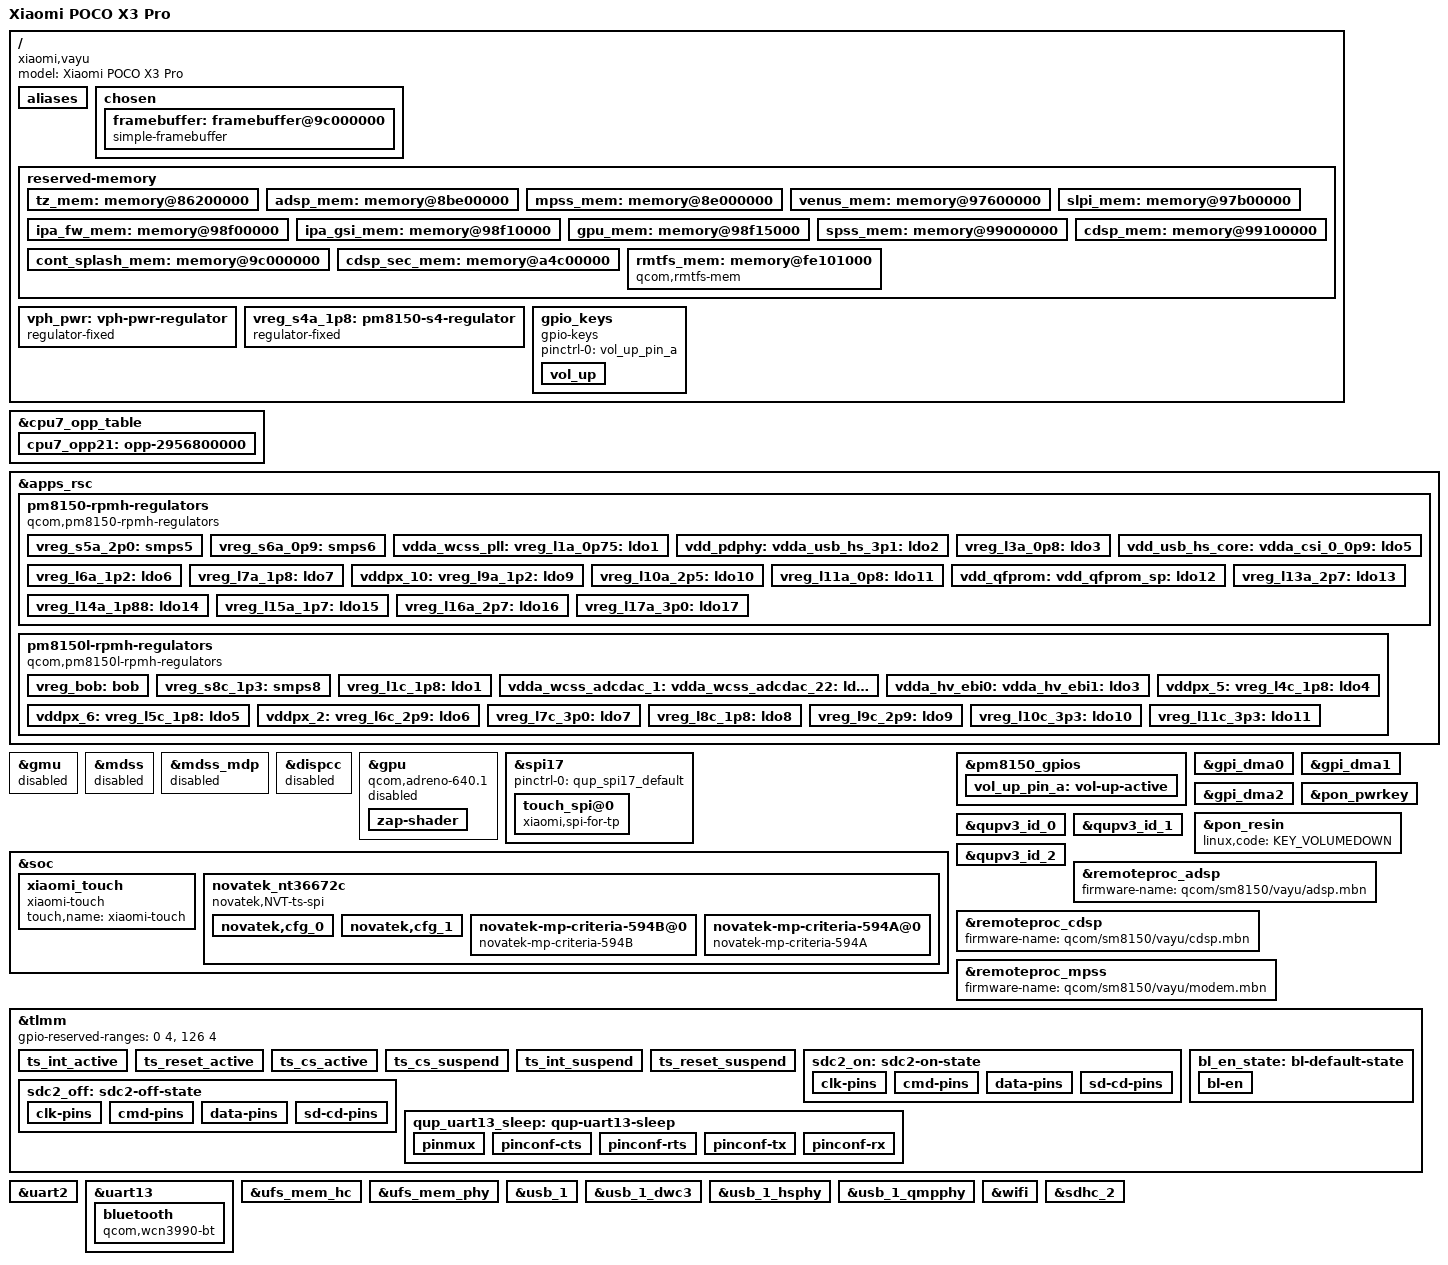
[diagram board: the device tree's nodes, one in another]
// SPDX-License-Identifier: GPL-2.0
/*
 * Device Tree Source for Xiaomi POCO X3 Pro (vayu)
 *
 * Copyright (c) 2023, Arseniy Velikanov <adomerlee@gmail.com>
 */

/dts-v1/;

#include <dt-bindings/gpio/gpio.h>
#include <dt-bindings/input/input.h>
#include <dt-bindings/input/gpio-keys.h>
#include <dt-bindings/pinctrl/qcom,pmic-gpio.h>
#include <dt-bindings/regulator/qcom,rpmh-regulator.h>
#include "sm8150.dtsi"
#include "pm8150.dtsi"
#include "pm8150b.dtsi"
#include "pm8150l.dtsi"

/* 
 * Rewrite reserved memory maps inherited from sm8150.dtsi to match the ones
 * used on xiaomi-vayu.
 * Note: this list is ordered by its memory address in sm8150.dtsi.
 */
/delete-node/ &tz_mem;      /* same address but larger, no place for rmtfs_mem! */
/delete-node/ &rmtfs_mem;   /* moved to completely different address */
/delete-node/ &adsp_mem;    /* same start address, but larger size */
/delete-node/ &mpss_mem;    /* same size, shifted higher, due to larger adsp_mem */
/delete-node/ &venus_mem;   /* same size, shifted higher */
/delete-node/ &slpi_mem;    /* same size, shifted higher */
/delete-node/ &ipa_fw_mem;  /* same size, shifted higher */
/delete-node/ &ipa_gsi_mem; /* same size, shifted higher */
/delete-node/ &gpu_mem;     /* same size, shifted higher */
/delete-node/ &spss_mem;    /* same size, shifted higher */
/delete-node/ &cdsp_mem;    /* same size, shifted higher */

/ {
	model = "Xiaomi POCO X3 Pro";
	compatible = "xiaomi,vayu", "qcom,sm8150";

	aliases {
		serial0 = &uart2;
		display0 = &framebuffer;
	};

	chosen {
		#address-cells = <2>;
		#size-cells = <2>;
		ranges;
	
		framebuffer: framebuffer@9c000000 {
			compatible = "simple-framebuffer";
			reg = <0 0x9c000000 0 (1080 * 2400 * 4)>;
			width = <1080>;
			height = <2400>;
			stride = <(1080 * 4)>;
			format = "a8r8g8b8";
			/*
			 * That's (going to be) a lot of clocks, but it's necessary due
			 * to unused clk cleanup & no panel driver yet (& no dispcc either)..
			 */
			clocks = <&gcc GCC_DISP_HF_AXI_CLK>,
			    	 <&gcc GCC_DISP_SF_AXI_CLK>;
		};
	};
	

	reserved-memory {
		tz_mem: memory@86200000 {
			reg = <0x0 0x86200000 0x0 0x5500000>;
			no-map;
		};

		adsp_mem: memory@8be00000 {
			no-map;
			reg = <0x0 0x8be00000 0x0 0x2200000>;
		};

		mpss_mem: memory@8e000000 {
			no-map;
			reg = <0x0 0x8e000000 0x0 0x9600000>;
		};

		venus_mem: memory@97600000 {
			no-map;
			reg = <0x0 0x97600000 0x0 0x500000>;
		};

		slpi_mem: memory@97b00000 {
			no-map;
			reg = <0x0 0x97b00000 0x0 0x1400000>;
		};

		ipa_fw_mem: memory@98f00000 {
			no-map;
			reg = <0x0 0x98f00000 0x0 0x10000>;
		};

		ipa_gsi_mem: memory@98f10000 {
			no-map;
			reg = <0x0 0x98f10000 0x0 0x5000>;
		};

		gpu_mem: memory@98f15000 {
			no-map;
			reg = <0x0 0x98f15000 0x0 0x2000>;
		};

		spss_mem: memory@99000000 {
			no-map;
			reg = <0x0 0x99000000 0x0 0x100000>;
		};

		cdsp_mem: memory@99100000 {
			no-map;
			reg = <0x0 0x99100000 0x0 0x1400000>;
		};

		cont_splash_mem: memory@9c000000 {
			reg = <0x0 0x9c000000 0x0 0x2400000>;
			no-map;
		};

		cdsp_sec_mem: memory@a4c00000 {
			reg = <0x0 0xa4c00000 0x0 0x3c00000>;
			no-map;
		};
		
		rmtfs_mem: memory@fe101000 {
			compatible = "qcom,rmtfs-mem";
			reg = <0 0xfe101000 0 0x300000>;
			no-map;

			qcom,client-id = <1>;
			qcom,vmid = <15>;
		};
	};

	vph_pwr: vph-pwr-regulator {
		compatible = "regulator-fixed";
		regulator-name = "vph_pwr";
		regulator-min-microvolt = <3700000>;
		regulator-max-microvolt = <3700000>;
	};

	/* S4 is modeled as a fixed regulator in vendor sources */
	vreg_s4a_1p8: pm8150-s4-regulator {
		compatible = "regulator-fixed";
		regulator-name = "vreg_s4a_1p8";

		regulator-min-microvolt = <1800000>;
		regulator-max-microvolt = <1800000>;

		regulator-always-on;
		regulator-boot-on;

		vin-supply = <&vph_pwr>;
	};
	
	gpio_keys {
		compatible = "gpio-keys";
		pinctrl-names = "default";
		pinctrl-0 = <&vol_up_pin_a>;
		
		vol_up {
			label = "volume_up";
			gpios = <&pm8150_gpios 6 GPIO_ACTIVE_LOW>;
			linux,input-type = <EV_KEY>;
			linux,code = <KEY_VOLUMEUP>;
			wakeup-source;
			debounce-interval = <15>;
		};
	};
};

//SD860 additional cpu frequency
&cpu7_opp_table {
	cpu7_opp21: opp-2956800000 {
		opp-hz = /bits/ 64 <2956800000>;
		opp-peak-kBps = <8368000 51609600>;
	};
};

&apps_rsc {
	pm8150-rpmh-regulators {
		compatible = "qcom,pm8150-rpmh-regulators";
		qcom,pmic-id = "a";

		vdd-s1-supply = <&vph_pwr>;
		vdd-s2-supply = <&vph_pwr>;
		vdd-s3-supply = <&vph_pwr>;
		vdd-s4-supply = <&vph_pwr>;
		vdd-s5-supply = <&vph_pwr>;
		vdd-s6-supply = <&vph_pwr>;
		vdd-s7-supply = <&vph_pwr>;
		vdd-s8-supply = <&vph_pwr>;
		vdd-s9-supply = <&vph_pwr>;
		vdd-s10-supply = <&vph_pwr>;

		vdd-l1-l8-l11-supply = <&vreg_s6a_0p9>;
		vdd-l2-l10-supply = <&vreg_bob>;
		vdd-l3-l4-l5-l18-supply = <&vreg_s6a_0p9>;
		vdd-l6-l9-supply = <&vreg_s8c_1p3>;
		vdd-l7-l12-l14-l15-supply = <&vreg_s5a_2p0>;
		vdd-l13-l16-l17-supply = <&vreg_bob>;

		vreg_s5a_2p0: smps5 {
			regulator-min-microvolt = <1904000>;
			regulator-max-microvolt = <2000000>;
		};

		vreg_s6a_0p9: smps6 {
			regulator-min-microvolt = <920000>;
			regulator-max-microvolt = <1128000>;
		};

		vdda_wcss_pll:
		vreg_l1a_0p75: ldo1 {
			regulator-min-microvolt = <752000>;
			regulator-max-microvolt = <752000>;
			regulator-initial-mode = <RPMH_REGULATOR_MODE_HPM>;
		};

		vdd_pdphy:
		vdda_usb_hs_3p1:
		vreg_l2a_3p1: ldo2 {
			regulator-min-microvolt = <3072000>;
			regulator-max-microvolt = <3072000>;
			regulator-initial-mode = <RPMH_REGULATOR_MODE_HPM>;
		};

		vreg_l3a_0p8: ldo3 {
			regulator-min-microvolt = <480000>;
			regulator-max-microvolt = <932000>;
			regulator-initial-mode = <RPMH_REGULATOR_MODE_HPM>;
		};

		vdd_usb_hs_core:
		vdda_csi_0_0p9:
		vdda_csi_1_0p9:
		vdda_csi_2_0p9:
		vdda_csi_3_0p9:
		vdda_dsi_0_0p9:
		vdda_dsi_1_0p9:
		vdda_dsi_0_pll_0p9:
		vdda_dsi_1_pll_0p9:
		vdda_pcie_1ln_core:
		vdda_pcie_2ln_core:
		vdda_pll_hv_cc_ebi01:
		vdda_pll_hv_cc_ebi23:
		vdda_qrefs_0p875_5:
		vdda_sp_sensor:
		vdda_ufs_2ln_core_1:
		vdda_ufs_2ln_core_2:
		vdda_usb_ss_dp_core_1:
		vdda_usb_ss_dp_core_2:
		vdda_qlink_lv:
		vdda_qlink_lv_ck:
		vreg_l5a_0p875: ldo5 {
			regulator-min-microvolt = <880000>;
			regulator-max-microvolt = <880000>;
			regulator-initial-mode = <RPMH_REGULATOR_MODE_HPM>;
		};

		vreg_l6a_1p2: ldo6 {
			regulator-min-microvolt = <1200000>;
			regulator-max-microvolt = <1200000>;
			regulator-initial-mode = <RPMH_REGULATOR_MODE_HPM>;
		};

		vreg_l7a_1p8: ldo7 {
			regulator-min-microvolt = <1800000>;
			regulator-max-microvolt = <1800000>;
			regulator-initial-mode = <RPMH_REGULATOR_MODE_HPM>;
		};

		vddpx_10:
		vreg_l9a_1p2: ldo9 {
			regulator-min-microvolt = <1200000>;
			regulator-max-microvolt = <1200000>;
			regulator-initial-mode = <RPMH_REGULATOR_MODE_HPM>;
		};

		vreg_l10a_2p5: ldo10 {
			regulator-min-microvolt = <2504000>;
			regulator-max-microvolt = <2960000>;
			regulator-initial-mode = <RPMH_REGULATOR_MODE_HPM>;
		};

		vreg_l11a_0p8: ldo11 {
			regulator-min-microvolt = <800000>;
			regulator-max-microvolt = <800000>;
			regulator-initial-mode = <RPMH_REGULATOR_MODE_HPM>;
		};

		vdd_qfprom:
		vdd_qfprom_sp:
		vdda_apc_cs_1p8:
		vdda_gfx_cs_1p8:
		vdda_usb_hs_1p8:
		vdda_qrefs_vref_1p8:
		vddpx_10_a:
		vreg_l12a_1p8: ldo12 {
			regulator-min-microvolt = <1800000>;
			regulator-max-microvolt = <1800000>;
			regulator-initial-mode = <RPMH_REGULATOR_MODE_HPM>;
		};

		vreg_l13a_2p7: ldo13 {
			regulator-min-microvolt = <2704000>;
			regulator-max-microvolt = <2704000>;
			regulator-initial-mode = <RPMH_REGULATOR_MODE_HPM>;
		};

		vreg_l14a_1p88: ldo14 {
			regulator-min-microvolt = <1800000>;
			regulator-max-microvolt = <1880000>;
			regulator-initial-mode = <RPMH_REGULATOR_MODE_HPM>;
		};

		vreg_l15a_1p7: ldo15 {
			regulator-min-microvolt = <1704000>;
			regulator-max-microvolt = <1704000>;
			regulator-initial-mode = <RPMH_REGULATOR_MODE_HPM>;
		};

		vreg_l16a_2p7: ldo16 {
			regulator-min-microvolt = <2704000>;
			regulator-max-microvolt = <2960000>;
			regulator-initial-mode = <RPMH_REGULATOR_MODE_HPM>;
		};

		vreg_l17a_3p0: ldo17 {
			regulator-min-microvolt = <2856000>;
			regulator-max-microvolt = <3008000>;
			regulator-initial-mode = <RPMH_REGULATOR_MODE_HPM>;
		};
	};

	pm8150l-rpmh-regulators {
		compatible = "qcom,pm8150l-rpmh-regulators";
		qcom,pmic-id = "c";

		vdd-s1-supply = <&vph_pwr>;
		vdd-s2-supply = <&vph_pwr>;
		vdd-s3-supply = <&vph_pwr>;
		vdd-s4-supply = <&vph_pwr>;
		vdd-s5-supply = <&vph_pwr>;
		vdd-s6-supply = <&vph_pwr>;
		vdd-s7-supply = <&vph_pwr>;
		vdd-s8-supply = <&vph_pwr>;

		vdd-l1-l8-supply = <&vreg_s4a_1p8>;
		vdd-l2-l3-supply = <&vreg_s8c_1p3>;
		vdd-l4-l5-l6-supply = <&vreg_bob>;
		vdd-l7-l11-supply = <&vreg_bob>;
		vdd-l9-l10-supply = <&vreg_bob>;

		vdd-bob-supply = <&vph_pwr>;
		vdd-flash-supply = <&vreg_bob>;
		vdd-rgb-supply = <&vreg_bob>;

		vreg_bob: bob {
			regulator-min-microvolt = <3008000>;
			regulator-max-microvolt = <4000000>;
			regulator-initial-mode = <RPMH_REGULATOR_MODE_AUTO>;
			regulator-allow-bypass;
		};

		vreg_s8c_1p3: smps8 {
			regulator-min-microvolt = <1352000>;
			regulator-max-microvolt = <1352000>;
		};

		vreg_l1c_1p8: ldo1 {
			regulator-min-microvolt = <1800000>;
			regulator-max-microvolt = <1800000>;
			regulator-initial-mode = <RPMH_REGULATOR_MODE_HPM>;
		};

		vdda_wcss_adcdac_1:
		vdda_wcss_adcdac_22:
		vreg_l2c_1p3: ldo2 {
			regulator-min-microvolt = <1304000>;
			regulator-max-microvolt = <1304000>;
			regulator-initial-mode = <RPMH_REGULATOR_MODE_HPM>;
		};

		vdda_hv_ebi0:
		vdda_hv_ebi1:
		vdda_hv_ebi2:
		vdda_hv_ebi3:
		vdda_hv_refgen0:
		vdda_mipi_dsi0_1p2:
		vdda_mipi_dsi1_1p2:
		vdda_qlink_hv_ck:
		vreg_l3c_1p2: ldo3 {
			regulator-min-microvolt = <1200000>;
			regulator-max-microvolt = <1200000>;
			regulator-initial-mode = <RPMH_REGULATOR_MODE_HPM>;
		};

		vddpx_5:
		vreg_l4c_1p8: ldo4 {
			regulator-min-microvolt = <1704000>;
			regulator-max-microvolt = <2928000>;
			regulator-initial-mode = <RPMH_REGULATOR_MODE_HPM>;
		};

		vddpx_6:
		vreg_l5c_1p8: ldo5 {
			regulator-min-microvolt = <1704000>;
			regulator-max-microvolt = <2928000>;
			regulator-initial-mode = <RPMH_REGULATOR_MODE_HPM>;
		};

		vddpx_2:
		vreg_l6c_2p9: ldo6 {
			regulator-min-microvolt = <1800000>;
			regulator-max-microvolt = <2960000>;
			regulator-initial-mode = <RPMH_REGULATOR_MODE_HPM>;
		};

		vreg_l7c_3p0: ldo7 {
			regulator-min-microvolt = <2856000>;
			regulator-max-microvolt = <3104000>;
			regulator-initial-mode = <RPMH_REGULATOR_MODE_HPM>;
		};

		vreg_l8c_1p8: ldo8 {
			regulator-min-microvolt = <1800000>;
			regulator-max-microvolt = <1800000>;
			regulator-initial-mode = <RPMH_REGULATOR_MODE_HPM>;
		};

		vreg_l9c_2p9: ldo9 {
			regulator-min-microvolt = <2704000>;
			regulator-max-microvolt = <2960000>;
			regulator-initial-mode = <RPMH_REGULATOR_MODE_HPM>;
		};

		vreg_l10c_3p3: ldo10 {
			regulator-min-microvolt = <3000000>;
			regulator-max-microvolt = <3312000>;
			regulator-initial-mode = <RPMH_REGULATOR_MODE_HPM>;
		};

		vreg_l11c_3p3: ldo11 {
			regulator-min-microvolt = <3000000>;
			regulator-max-microvolt = <3312000>;
			regulator-initial-mode = <RPMH_REGULATOR_MODE_HPM>;
		};
	};
};

&gmu {
	status = "disabled";
};

&mdss {
	status = "disabled";
};

&mdss_mdp {
	status = "disabled";
};

&dispcc {
	status = "disabled";
};

&gpu {
	/*
	 * NOTE: "amd,imageon" makes Adreno start in headless mode, remove it
	 * after display support is added on this board.
	 */
	compatible = "qcom,adreno-640.1", "qcom,adreno", "amd,imageon";

	status = "disabled";
	
	zap-shader {
		memory-region = <&gpu_mem>;
		firmware-name = "qcom/a640_zap.mbn";
	};
};

&spi17 {
	status = "okay";
	pinctrl-0 = <&qup_spi17_default>;
	
	touch_spi@0 {
		compatible = "xiaomi,spi-for-tp";
		reg = <0>;
		status = "okay";
		spi-max-frequency = <10000000>;  //10M
	};
};

&soc {
	xiaomi_touch {
		compatible = "xiaomi-touch";
		status = "okay";
		touch,name = "xiaomi-touch";
	};
	
	novatek_nt36672c {
		compatible = "novatek,NVT-ts-spi";
		reg = <0x00 0xc84000 0x00 0x400>;
		status = "okay";
		spi-max-frequency = <10000000>; //10M
		novatek,reset-gpio = <&tlmm 12 0x00>;
		novatek,irq-gpio = <&tlmm 122 0x2001>;
		pinctrl-names = "pmx_ts_active", "pmx_ts_suspend";
		pinctrl-0 = <&ts_int_active &ts_reset_active &ts_cs_active>;
		pinctrl-1 = <&ts_int_suspend &ts_reset_suspend &ts_cs_suspend>;
		novatek,swrst-n8-addr = <0x03F0FE>;
		novatek,spi-rd-fast-addr = <0x03F310>;
		novatek,mp-support-dt;
		novatek,config-array-size = <2>;

		novatek,cfg_0 {
			novatek,tp-vendor = <0x46>;
			novatek,display-maker = <0x36>;
			novatek,fw-name = "j20s_novatek_ts_fw01.bin";
			novatek,mp-name = "j20s_novatek_ts_mp01.bin";
			novatek,clicknum-file-name = "nvt+tianma";
		};

		novatek,cfg_1 {
			novatek,tp-vendor = <0x53>;
			novatek,display-maker = <0x42>;
			novatek,fw-name = "j20s_novatek_ts_fw02.bin";
			novatek,mp-name = "j20s_novatek_ts_mp02.bin";
			novatek,clicknum-file-name = "nvt+csot";
		};

		novatek-mp-criteria-594B@0 {
			#address-cells = <0x01>;
			#size-cells = <0x00>;
			compatible = "novatek-mp-criteria-594B";
			IC_X_CFG_SIZE = <0x12>;
			IC_Y_CFG_SIZE = <0x24>;
			IC_KEY_CFG_SIZE = <0x04>;
			X_Channel = <0x12>;
			Y_Channel = <0x24>;
			AIN_X = <0x00 0x01 0x02 0x03 0x04 0x05 0x06 0x07 0x08 0x09 0x0a 0x0b 0x0c 0x0d 0x0e 0x0f 0x10 0x11>;
			AIN_Y = <0x00 0x01 0x02 0x03 0x04 0x05 0x06 0x07 0x08 0x09 0x0a 0x0b 0x0c 0x0d 0x0e 0x0f 0x10 0x11 0x12 0x13 0x14 0x15 0x16 0x17 0x18 0x19 0x1a 0x1b 0x1c 0x1d 0x1e 0x1f 0x20 0x21 0x22 0x23>;
			AIN_KEY = <0x00 0x01 0x02 0xff>;
			PS_Config_Lmt_Short_Rawdata_P = <0x36b8 0x36b8 0x36b8 0x36b8 0x36b8 0x36b8 0x36b8 0x36b8 0x36b8 0x36b8 0x36b8 0x36b8 0x36b8 0x36b8 0x36b8 0x36b8 0x36b8 0x36b8 0x36b8 0x36b8 0x36b8 0x36b8 0x36b8 0x36b8 0x36b8 0x36b8 0x36b8 0x36b8 0x36b8 0x36b8 0x36b8 0x36b8 0x36b8 0x36b8 0x36b8 0x36b8 0x36b8 0x36b8 0x36b8 0x36b8 0x36b8 0x36b8 0x36b8 0x36b8 0x36b8 0x36b8 0x36b8 0x36b8 0x36b8 0x36b8 0x36b8 0x36b8 0x36b8 0x36b8 0x36b8 0x36b8 0x36b8 0x36b8 0x36b8 0x36b8 0x36b8 0x36b8 0x36b8 0x36b8 0x36b8 0x36b8 0x36b8 0x36b8 0x36b8 0x36b8 0x36b8 0x36b8 0x36b8 0x36b8 0x36b8 0x36b8 0x36b8 0x36b8 0x36b8 0x36b8 0x36b8 0x36b8 0x36b8 0x36b8 0x36b8 0x36b8 0x36b8 0x36b8 0x36b8 0x36b8 0x36b8 0x36b8 0x36b8 0x36b8 0x36b8 0x36b8 0x36b8 0x36b8 0x36b8 0x36b8 0x36b8 0x36b8 0x36b8 0x36b8 0x36b8 0x36b8 0x36b8 0x36b8 0x36b8 0x36b8 0x36b8 0x36b8 0x36b8 0x36b8 0x36b8 0x36b8 0x36b8 0x36b8 0x36b8 0x36b8 0x36b8 0x36b8 0x36b8 0x36b8 0x36b8 0x36b8 0x36b8 0x36b8 0x36b8 0x36b8 0x36b8 0x36b8 0x36b8 0x36b8 0x36b8 0x36b8 0x36b8 0x36b8 0x36b8 0x36b8 0x36b8 0x36b8 0x36b8 0x36b8 0x36b8 0x36b8 0x36b8 0x36b8 0x36b8 0x36b8 0x36b8 0x36b8 0x36b8 0x36b8 0x36b8 0x36b8 0x36b8 0x36b8 0x36b8 0x36b8 0x36b8 0x36b8 0x36b8 0x36b8 0x36b8 0x36b8 0x36b8 0x36b8 0x36b8 0x36b8 0x36b8 0x36b8 0x36b8 0x36b8 0x36b8 0x36b8 0x36b8 0x36b8 0x36b8 0x36b8 0x36b8 0x36b8 0x36b8 0x36b8 0x36b8 0x36b8 0x36b8 0x36b8 0x36b8 0x36b8 0x36b8 0x36b8 0x36b8 0x36b8 0x36b8 0x36b8 0x36b8 0x36b8 0x36b8 0x36b8 0x36b8 0x36b8 0x36b8 0x36b8 0x36b8 0x36b8 0x36b8 0x36b8 0x36b8 0x36b8 0x36b8 0x36b8 0x36b8 0x36b8 0x36b8 0x36b8 0x36b8 0x36b8 0x36b8 0x36b8 0x36b8 0x36b8 0x36b8 0x36b8 0x36b8 0x36b8 0x36b8 0x36b8 0x36b8 0x36b8 0x36b8 0x36b8 0x36b8 0x36b8 0x36b8 0x36b8 0x36b8 0x36b8 0x36b8 0x36b8 0x36b8 0x36b8 0x36b8 0x36b8 0x36b8 0x36b8 0x36b8 0x36b8 0x36b8 0x36b8 0x36b8 0x36b8 0x36b8 0x36b8 0x36b8 0x36b8 0x36b8 0x36b8 0x36b8 0x36b8 0x36b8 0x36b8 0x36b8 0x36b8 0x36b8 0x36b8 0x36b8 0x36b8 0x36b8 0x36b8 0x36b8 0x36b8 0x36b8 0x36b8 0x36b8 0x36b8 0x36b8 0x36b8 0x36b8 0x36b8 0x36b8 0x36b8 0x36b8 0x36b8 0x36b8 0x36b8 0x36b8 0x36b8 0x36b8 0x36b8 0x36b8 0x36b8 0x36b8 0x36b8 0x36b8 0x36b8 0x36b8 0x36b8 0x36b8 0x36b8 0x36b8 0x36b8 0x36b8 0x36b8 0x36b8 0x36b8 0x36b8 0x36b8 0x36b8 0x36b8 0x36b8 0x36b8 0x36b8 0x36b8 0x36b8 0x36b8 0x36b8 0x36b8 0x36b8 0x36b8 0x36b8 0x36b8 0x36b8 0x36b8 0x36b8 0x36b8 0x36b8 0x36b8 0x36b8 0x36b8 0x36b8 0x36b8 0x36b8 0x36b8 0x36b8 0x36b8 0x36b8 0x36b8 0x36b8 0x36b8 0x36b8 0x36b8 0x36b8 0x36b8 0x36b8 0x36b8 0x36b8 0x36b8 0x36b8 0x36b8 0x36b8 0x36b8 0x36b8 0x36b8 0x36b8 0x36b8 0x36b8 0x36b8 0x36b8 0x36b8 0x36b8 0x36b8 0x36b8 0x36b8 0x36b8 0x36b8 0x36b8 0x36b8 0x36b8 0x36b8 0x36b8 0x36b8 0x36b8 0x36b8 0x36b8 0x36b8 0x36b8 0x36b8 0x36b8 0x36b8 0x36b8 0x36b8 0x36b8 0x36b8 0x36b8 0x36b8 0x36b8 0x36b8 0x36b8 0x36b8 0x36b8 0x36b8 0x36b8 0x36b8 0x36b8 0x36b8 0x36b8 0x36b8 0x36b8 0x36b8 0x36b8 0x36b8 0x36b8 0x36b8 0x36b8 0x36b8 0x36b8 0x36b8 0x36b8 0x36b8 0x36b8 0x36b8 0x36b8 0x36b8 0x36b8 0x36b8 0x36b8 0x36b8 0x36b8 0x36b8 0x36b8 0x36b8 0x36b8 0x36b8 0x36b8 0x36b8 0x36b8 0x36b8 0x36b8 0x36b8 0x36b8 0x36b8 0x36b8 0x36b8 0x36b8 0x36b8 0x36b8 0x36b8 0x36b8 0x36b8 0x36b8 0x36b8 0x36b8 0x36b8 0x36b8 0x36b8 0x36b8 0x36b8 0x36b8 0x36b8 0x36b8 0x36b8 0x36b8 0x36b8 0x36b8 0x36b8 0x36b8 0x36b8 0x36b8 0x36b8 0x36b8 0x36b8 0x36b8 0x36b8 0x36b8 0x36b8 0x36b8 0x36b8 0x36b8 0x36b8 0x36b8 0x36b8 0x36b8 0x36b8 0x36b8 0x36b8 0x36b8 0x36b8 0x36b8 0x36b8 0x36b8 0x36b8 0x36b8 0x36b8 0x36b8 0x36b8 0x36b8 0x36b8 0x36b8 0x36b8 0x36b8 0x36b8 0x36b8 0x36b8 0x36b8 0x36b8 0x36b8 0x36b8 0x36b8 0x36b8 0x36b8 0x36b8 0x36b8 0x36b8 0x36b8 0x36b8 0x36b8 0x36b8 0x36b8 0x36b8 0x36b8 0x36b8 0x36b8 0x36b8 0x36b8 0x36b8 0x36b8 0x36b8 0x36b8 0x36b8 0x36b8 0x36b8 0x36b8 0x36b8 0x36b8 0x36b8 0x36b8 0x36b8 0x36b8 0x36b8 0x36b8 0x36b8 0x36b8 0x36b8 0x36b8 0x36b8 0x36b8 0x36b8 0x36b8 0x36b8 0x36b8 0x36b8 0x36b8 0x36b8 0x36b8 0x36b8 0x36b8 0x36b8 0x36b8 0x36b8 0x36b8 0x36b8 0x36b8 0x36b8 0x36b8 0x36b8 0x36b8 0x36b8 0x36b8 0x36b8 0x36b8 0x36b8 0x36b8 0x36b8 0x36b8 0x36b8 0x36b8 0x36b8 0x36b8 0x36b8 0x36b8 0x36b8 0x36b8 0x36b8 0x36b8 0x36b8 0x36b8 0x36b8 0x36b8 0x36b8 0x36b8 0x36b8 0x36b8 0x36b8 0x36b8 0x36b8 0x36b8 0x36b8 0x36b8 0x36b8 0x36b8 0x36b8 0x36b8 0x36b8 0x36b8 0x36b8 0x36b8 0x36b8 0x36b8 0x36b8 0x36b8 0x36b8 0x36b8 0x36b8 0x36b8 0x36b8 0x36b8 0x36b8 0x36b8 0x36b8 0x36b8 0x36b8 0x36b8 0x36b8 0x36b8 0x36b8 0x36b8 0x36b8 0x36b8 0x36b8 0x36b8 0x36b8 0x36b8 0x36b8 0x36b8 0x36b8 0x36b8 0x36b8 0x36b8 0x36b8 0x36b8 0x36b8 0x36b8 0x36b8 0x36b8 0x36b8 0x36b8 0x36b8 0x36b8 0x36b8 0x36b8 0x36b8 0x36b8 0x36b8 0x36b8 0x36b8 0x36b8 0x36b8 0x36b8 0x36b8 0x36b8>;
			PS_Config_Lmt_Short_Rawdata_N = <0x2710 0x2710 0x2710 0x2710 0x2710 0x2710 0x2710 0x2710 0x2710 0x2710 0x2710 0x2710 0x2710 0x2710 0x2710 0x2710 0x2710 0x2710 0x2710 0x2710 0x2710 0x2710 0x2710 0x2710 0x2710 0x2710 0x2710 0x2710 0x2710 0x2710 0x2710 0x2710 0x2710 0x2710 0x2710 0x2710 0x2710 0x2710 0x2710 0x2710 0x2710 0x2710 0x2710 0x2710 0x2710 0x2710 0x2710 0x2710 0x2710 0x2710 0x2710 0x2710 0x2710 0x2710 0x2710 0x2710 0x2710 0x2710 0x2710 0x2710 0x2710 0x2710 0x2710 0x2710 0x2710 0x2710 0x2710 0x2710 0x2710 0x2710 0x2710 0x2710 0x2710 0x2710 0x2710 0x2710 0x2710 0x2710 0x2710 0x2710 0x2710 0x2710 0x2710 0x2710 0x2710 0x2710 0x2710 0x2710 0x2710 0x2710 0x2710 0x2710 0x2710 0x2710 0x2710 0x2710 0x2710 0x2710 0x2710 0x2710 0x2710 0x2710 0x2710 0x2710 0x2710 0x2710 0x2710 0x2710 0x2710 0x2710 0x2710 0x2710 0x2710 0x2710 0x2710 0x2710 0x2710 0x2710 0x2710 0x2710 0x2710 0x2710 0x2710 0x2710 0x2710 0x2710 0x2710 0x2710 0x2710 0x2710 0x2710 0x2710 0x2710 0x2710 0x2710 0x2710 0x2710 0x2710 0x2710 0x2710 0x2710 0x2710 0x2710 0x2710 0x2710 0x2710 0x2710 0x2710 0x2710 0x2710 0x2710 0x2710 0x2710 0x2710 0x2710 0x2710 0x2710 0x2710 0x2710 0x2710 0x2710 0x2710 0x2710 0x2710 0x2710 0x2710 0x2710 0x2710 0x2710 0x2710 0x2710 0x2710 0x2710 0x2710 0x2710 0x2710 0x2710 0x2710 0x2710 0x2710 0x2710 0x2710 0x2710 0x2710 0x2710 0x2710 0x2710 0x2710 0x2710 0x2710 0x2710 0x2710 0x2710 0x2710 0x2710 0x2710 0x2710 0x2710 0x2710 0x2710 0x2710 0x2710 0x2710 0x2710 0x2710 0x2710 0x2710 0x2710 0x2710 0x2710 0x2710 0x2710 0x2710 0x2710 0x2710 0x2710 0x2710 0x2710 0x2710 0x2710 0x2710 0x2710 0x2710 0x2710 0x2710 0x2710 0x2710 0x2710 0x2710 0x2710 0x2710 0x2710 0x2710 0x2710 0x2710 0x2710 0x2710 0x2710 0x2710 0x2710 0x2710 0x2710 0x2710 0x2710 0x2710 0x2710 0x2710 0x2710 0x2710 0x2710 0x2710 0x2710 0x2710 0x2710 0x2710 0x2710 0x2710 0x2710 0x2710 0x2710 0x2710 0x2710 0x2710 0x2710 0x2710 0x2710 0x2710 0x2710 0x2710 0x2710 0x2710 0x2710 0x2710 0x2710 0x2710 0x2710 0x2710 0x2710 0x2710 0x2710 0x2710 0x2710 0x2710 0x2710 0x2710 0x2710 0x2710 0x2710 0x2710 0x2710 0x2710 0x2710 0x2710 0x2710 0x2710 0x2710 0x2710 0x2710 0x2710 0x2710 0x2710 0x2710 0x2710 0x2710 0x2710 0x2710 0x2710 0x2710 0x2710 0x2710 0x2710 0x2710 0x2710 0x2710 0x2710 0x2710 0x2710 0x2710 0x2710 0x2710 0x2710 0x2710 0x2710 0x2710 0x2710 0x2710 0x2710 0x2710 0x2710 0x2710 0x2710 0x2710 0x2710 0x2710 0x2710 0x2710 0x2710 0x2710 0x2710 0x2710 0x2710 0x2710 0x2710 0x2710 0x2710 0x2710 0x2710 0x2710 0x2710 0x2710 0x2710 0x2710 0x2710 0x2710 0x2710 0x2710 0x2710 0x2710 0x2710 0x2710 0x2710 0x2710 0x2710 0x2710 0x2710 0x2710 0x2710 0x2710 0x2710 0x2710 0x2710 0x2710 0x2710 0x2710 0x2710 0x2710 0x2710 0x2710 0x2710 0x2710 0x2710 0x2710 0x2710 0x2710 0x2710 0x2710 0x2710 0x2710 0x2710 0x2710 0x2710 0x2710 0x2710 0x2710 0x2710 0x2710 0x2710 0x2710 0x2710 0x2710 0x2710 0x2710 0x2710 0x2710 0x2710 0x2710 0x2710 0x2710 0x2710 0x2710 0x2710 0x2710 0x2710 0x2710 0x2710 0x2710 0x2710 0x2710 0x2710 0x2710 0x2710 0x2710 0x2710 0x2710 0x2710 0x2710 0x2710 0x2710 0x2710 0x2710 0x2710 0x2710 0x2710 0x2710 0x2710 0x2710 0x2710 0x2710 0x2710 0x2710 0x2710 0x2710 0x2710 0x2710 0x2710 0x2710 0x2710 0x2710 0x2710 0x2710 0x2710 0x2710 0x2710 0x2710 0x2710 0x2710 0x2710 0x2710 0x2710 0x2710 0x2710 0x2710 0x2710 0x2710 0x2710 0x2710 0x2710 0x2710 0x2710 0x2710 0x2710 0x2710 0x2710 0x2710 0x2710 0x2710 0x2710 0x2710 0x2710 0x2710 0x2710 0x2710 0x2710 0x2710 0x2710 0x2710 0x2710 0x2710 0x2710 0x2710 0x2710 0x2710 0x2710 0x2710 0x2710 0x2710 0x2710 0x2710 0x2710 0x2710 0x2710 0x2710 0x2710 0x2710 0x2710 0x2710 0x2710 0x2710 0x2710 0x2710 0x2710 0x2710 0x2710 0x2710 0x2710 0x2710 0x2710 0x2710 0x2710 0x2710 0x2710 0x2710 0x2710 0x2710 0x2710 0x2710 0x2710 0x2710 0x2710 0x2710 0x2710 0x2710 0x2710 0x2710 0x2710 0x2710 0x2710 0x2710 0x2710 0x2710 0x2710 0x2710 0x2710 0x2710 0x2710 0x2710 0x2710 0x2710 0x2710 0x2710 0x2710 0x2710 0x2710 0x2710 0x2710 0x2710 0x2710 0x2710 0x2710 0x2710 0x2710 0x2710 0x2710 0x2710 0x2710 0x2710 0x2710 0x2710 0x2710 0x2710 0x2710 0x2710 0x2710 0x2710 0x2710 0x2710 0x2710 0x2710 0x2710 0x2710 0x2710 0x2710 0x2710 0x2710 0x2710 0x2710 0x2710 0x2710 0x2710 0x2710 0x2710 0x2710 0x2710 0x2710 0x2710 0x2710 0x2710 0x2710 0x2710 0x2710 0x2710 0x2710 0x2710 0x2710 0x2710 0x2710 0x2710 0x2710 0x2710 0x2710 0x2710 0x2710 0x2710 0x2710 0x2710 0x2710 0x2710 0x2710 0x2710 0x2710 0x2710 0x2710 0x2710 0x2710 0x2710 0x2710 0x2710 0x2710 0x2710 0x2710 0x2710 0x2710 0x2710 0x2710 0x2710 0x2710 0x2710 0x2710 0x2710 0x2710 0x2710 0x2710 0x2710 0x2710 0x2710 0x2710 0x2710 0x2710 0x2710 0x2710 0x2710>;
			PS_Config_Lmt_Open_Rawdata_P = <0x1400 0x1400 0x1400 0x1400 0x1400 0x1400 0x1400 0x1400 0x1400 0x1400 0x1400 0x1400 0x1400 0x1400 0x1400 0x1400 0x1400 0x1400 0x1400 0x1400 0x1400 0x1400 0x1400 0x1400 0x1400 0x1400 0x1400 0x1400 0x1400 0x1400 0x1400 0x1400 0x1400 0x1400 0x1400 0x1400 0x1400 0x1400 0x1400 0x1400 0x1400 0x1400 0x1400 0x1400 0x1400 0x1400 0x1400 0x1400 0x1400 0x1400 0x1400 0x1400 0x1400 0x1400 0x1400 0x1400 0x1400 0x1400 0x1400 0x1400 0x1400 0x1400 0x1400 0x1400 0x1400 0x1400 0x1400 0x1400 0x1400 0x1400 0x1400 0x1400 0x1400 0x1400 0x1400 0x1400 0x1400 0x1400 0x1400 0x1400 0x1400 0x1400 0x1400 0x1400 0x1400 0x1400 0x1400 0x1400 0x1400 0x1400 0x1400 0x1400 0x1400 0x1400 0x1400 0x1400 0x1400 0x1400 0x1400 0x1400 0x1400 0x1400 0x1400 0x1400 0x1400 0x1400 0x1400 0x1400 0x1400 0x1400 0x1400 0x1400 0x1400 0x1400 0x1400 0x1400 0x1400 0x1400 0x1400 0x1400 0x1400 0x1400 0x1400 0x1400 0x1400 0x1400 0x1400 0x1400 0x1400 0x1400 0x1400 0x1400 0x1400 0x1400 0x1400 0x1400 0x1400 0x1400 0x1400 0x1400 0x1400 0x1400 0x1400 0x1400 0x1400 0x1400 0x1400 0x1400 0x1400 0x1400 0x1400 0x1400 0x1400 0x1400 0x1400 0x1400 0x1400 0x1400 0x1400 0x1400 0x1400 0x1400 0x1400 0x1400 0x1400 0x1400 0x1400 0x1400 0x1400 0x1400 0x1400 0x1400 0x1400 0x1400 0x1400 0x1400 0x1400 0x1400 0x1400 0x1400 0x1400 0x1400 0x1400 0x1400 0x1400 0x1400 0x1400 0x1400 0x1400 0x1400 0x1400 0x1400 0x1400 0x1400 0x1400 0x1400 0x1400 0x1400 0x1400 0x1400 0x1400 0x1400 0x1400 0x1400 0x1400 0x1400 0x1400 0x1400 0x1400 0x1400 0x1400 0x1400 0x1400 0x1400 0x1400 0x1400 0x1400 0x1400 0x1400 0x1400 0x1400 0x1400 0x1400 0x1400 0x1400 0x1400 0x1400 0x1400 0x1400 0x1400 0x1400 0x1400 0x1400 0x1400 0x1400 0x1400 0x1400 0x1400 0x1400 0x1400 0x1400 0x1400 0x1400 0x1400 0x1400 0x1400 0x1400 0x1400 0x1400 0x1400 0x1400 0x1400 0x1400 0x1400 0x1400 0x1400 0x1400 0x1400 0x1400 0x1400 0x1400 0x1400 0x1400 0x1400 0x1400 0x1400 0x1400 0x1400 0x1400 0x1400 0x1400 0x1400 0x1400 0x1400 0x1400 0x1400 0x1400 0x1400 0x1400 0x1400 0x1400 0x1400 0x1400 0x1400 0x1400 0x1400 0x1400 0x1400 0x1400 0x1400 0x1400 0x1400 0x1400 0x1400 0x1400 0x1400 0x1400 0x1400 0x1400 0x1400 0x1400 0x1400 0x1400 0x1400 0x1400 0x1400 0x1400 0x1400 0x1400 0x1400 0x1400 0x1400 0x1400 0x1400 0x1400 0x1400 0x1400 0x1400 0x1400 0x1400 0x1400 0x1400 0x1400 0x1400 0x1400 0x1400 0x1400 0x1400 0x1400 0x1400 0x1400 0x1400 0x1400 0x1400 0x1400 0x1400 0x1400 0x1400 0x1400 0x1400 0x1400 0x1400 0x1400 0x1400 0x1400 0x1400 0x1400 0x1400 0x1400 0x1400 0x1400 0x1400 0x1400 0x1400 0x1400 0x1400 0x1400 0x1400 0x1400 0x1400 0x1400 0x1400 0x1400 0x1400 0x1400 0x1400 0x1400 0x1400 0x1400 0x1400 0x1400 0x1400 0x1400 0x1400 0x1400 0x1400 0x1400 0x1400 0x1400 0x1400 0x1400 0x1400 0x1400 0x1400 0x1400 0x1400 0x1400 0x1400 0x1400 0x1400 0x1400 0x1400 0x1400 0x1400 0x1400 0x1400 0x1400 0x1400 0x1400 0x1400 0x1400 0x1400 0x1400 0x1400 0x1400 0x1400 0x1400 0x1400 0x1400 0x1400 0x1400 0x1400 0x1400 0x1400 0x1400 0x1400 0x1400 0x1400 0x1400 0x1400 0x1400 0x1400 0x1400 0x1400 0x1400 0x1400 0x1400 0x1400 0x1400 0x1400 0x1400 0x1400 0x1400 0x1400 0x1400 0x1400 0x1400 0x1400 0x1400 0x1400 0x1400 0x1400 0x1400 0x1400 0x1400 0x1400 0x1400 0x1400 0x1400 0x1400 0x1400 0x1400 0x1400 0x1400 0x1400 0x1400 0x1400 0x1400 0x1400 0x1400 0x1400 0x1400 0x1400 0x1400 0x1400 0x1400 0x1400 0x1400 0x1400 0x1400 0x1400 0x1400 0x1400 0x1400 0x1400 0x1400 0x1400 0x1400 0x1400 0x1400 0x1400 0x1400 0x1400 0x1400 0x1400 0x1400 0x1400 0x1400 0x1400 0x1400 0x1400 0x1400 0x1400 0x1400 0x1400 0x1400 0x1400 0x1400 0x1400 0x1400 0x1400 0x1400 0x1400 0x1400 0x1400 0x1400 0x1400 0x1400 0x1400 0x1400 0x1400 0x1400 0x1400 0x1400 0x1400 0x1400 0x1400 0x1400 0x1400 0x1400 0x1400 0x1400 0x1400 0x1400 0x1400 0x1400 0x1400 0x1400 0x1400 0x1400 0x1400 0x1400 0x1400 0x1400 0x1400 0x1400 0x1400 0x1400 0x1400 0x1400 0x1400 0x1400 0x1400 0x1400 0x1400 0x1400 0x1400 0x1400 0x1400 0x1400 0x1400 0x1400 0x1400 0x1400 0x1400 0x1400 0x1400 0x1400 0x1400 0x1400 0x1400 0x1400 0x1400 0x1400 0x1400 0x1400 0x1400 0x1400 0x1400 0x1400 0x1400 0x1400 0x1400 0x1400 0x1400 0x1400 0x1400 0x1400 0x1400 0x1400 0x1400 0x1400 0x1400 0x1400 0x1400 0x1400 0x1400 0x1400 0x1400 0x1400 0x1400 0x1400 0x1400 0x1400 0x1400 0x1400 0x1400 0x1400 0x1400 0x1400 0x1400 0x1400 0x1400 0x1400 0x1400 0x1400 0x1400 0x1400 0x1400 0x1400 0x1400 0x1400 0x1400 0x1400 0x1400 0x1400 0x1400 0x1400 0x1400 0x1400 0x1400 0x1400 0x1400 0x1400 0x1400 0x1400 0x1400 0x1400 0x1400 0x1400 0x1400 0x1400 0x1400 0x1400 0x1400 0x1400 0x1400 0x1400 0x1400 0x1400 0x1400 0x1400 0x1400 0x1400 0x1400 0x1400 0x1400 0x1400 0x1400 0x1400 0x1400>;
			PS_Config_Lmt_Open_Rawdata_N = <0xfffffe01 0xfffffe01 0xfffffe01 0xfffffe01 0xfffffe01 0xfffffe01 0xfffffe01 0xfffffe01 0xfffffe01 0xfffffe01 0xfffffe01 0xfffffe01 0xfffffe01 0xfffffe01 0xfffffe01 0xfffffe01 0xfffffe01 0xfffffe01 0xfffffe01 0xfffffe01 0xfffffe01 0xfffffe01 0xfffffe01 0xfffffe01 0xfffffe01 0xfffffe01 0xfffffe01 0xfffffe01 0xfffffe01 0xfffffe01 0xfffffe01 0xfffffe01 0xfffffe01 0xfffffe01 0xfffffe01 0xfffffe01 0xfffffe01 0xfffffe01 0xfffffe01 0xfffffe01 0xfffffe01 0xfffffe01 0xfffffe01 0xfffffe01 0xfffffe01 0xfffffe01 0xfffffe01 0xfffffe01 0xfffffe01 0xfffffe01 0xfffffe01 0xfffffe01 0xfffffe01 0xfffffe01 0xfffffe01 0xfffffe01 0xfffffe01 0xfffffe01 0xfffffe01 0xfffffe01 0xfffffe01 0xfffffe01 0xfffffe01 0xfffffe01 0xfffffe01 0xfffffe01 0xfffffe01 0xfffffe01 0xfffffe01 0xfffffe01 0xfffffe01 0xfffffe01 0xfffffe01 0xfffffe01 0xfffffe01 0xfffffe01 0xfffffe01 0xfffffe01 0xfffffe01 0xfffffe01 0xfffffe01 0xfffffe01 0xfffffe01 0xfffffe01 0xfffffe01 0xfffffe01 0xfffffe01 0xfffffe01 0xfffffe01 0xfffffe01 0xfffffe01 0xfffffe01 0xfffffe01 0xfffffe01 0xfffffe01 0xfffffe01 0xfffffe01 0xfffffe01 0xfffffe01 0xfffffe01 0xfffffe01 0xfffffe01 0xfffffe01 0xfffffe01 0xfffffe01 0xfffffe01 0xfffffe01 0xfffffe01 0xfffffe01 0xfffffe01 0xfffffe01 0xfffffe01 0xfffffe01 0xfffffe01 0xfffffe01 0xfffffe01 0xfffffe01 0xfffffe01 0xfffffe01 0xfffffe01 0xfffffe01 0xfffffe01 0xfffffe01 0xfffffe01 0xfffffe01 0xfffffe01 0xfffffe01 0xfffffe01 0xfffffe01 0xfffffe01 0xfffffe01 0xfffffe01 0xfffffe01 0xfffffe01 0xfffffe01 0xfffffe01 0xfffffe01 0xfffffe01 0xfffffe01 0xfffffe01 0xfffffe01 0xfffffe01 0xfffffe01 0xfffffe01 0xfffffe01 0xfffffe01 0xfffffe01 0xfffffe01 0xfffffe01 0xfffffe01 0xfffffe01 0xfffffe01 0xfffffe01 0xfffffe01 0xfffffe01 0xfffffe01 0xfffffe01 0xfffffe01 0xfffffe01 0xfffffe01 0xfffffe01 0xfffffe01 0xfffffe01 0xfffffe01 0xfffffe01 0xfffffe01 0xfffffe01 0xfffffe01 0xfffffe01 0xfffffe01 0xfffffe01 0xfffffe01 0xfffffe01 0xfffffe01 0xfffffe01 0xfffffe01 0xfffffe01 0xfffffe01 0xfffffe01 0xfffffe01 0xfffffe01 0xfffffe01 0xfffffe01 0xfffffe01 0xfffffe01 0xfffffe01 0xfffffe01 0xfffffe01 0xfffffe01 0xfffffe01 0xfffffe01 0xfffffe01 0xfffffe01 0xfffffe01 0xfffffe01 0xfffffe01 0xfffffe01 0xfffffe01 0xfffffe01 0xfffffe01 0xfffffe01 0xfffffe01 0xfffffe01 0xfffffe01 0xfffffe01 0xfffffe01 0xfffffe01 0xfffffe01 0xfffffe01 0xfffffe01 0xfffffe01 0xfffffe01 0xfffffe01 0xfffffe01 0xfffffe01 0xfffffe01 0xfffffe01 0xfffffe01 0xfffffe01 0xfffffe01 0xfffffe01 0xfffffe01 0xfffffe01 0xfffffe01 0xfffffe01 0xfffffe01 0xfffffe01 0xfffffe01 0xfffffe01 0xfffffe01 0xfffffe01 0xfffffe01 0xfffffe01 0xfffffe01 0xfffffe01 0xfffffe01 0xfffffe01 0xfffffe01 0xfffffe01 0xfffffe01 0xfffffe01 0xfffffe01 0xfffffe01 0xfffffe01 0xfffffe01 0xfffffe01 0xfffffe01 0xfffffe01 0xfffffe01 0xfffffe01 0xfffffe01 0xfffffe01 0xfffffe01 0xfffffe01 0xfffffe01 0xfffffe01 0xfffffe01 0xfffffe01 0xfffffe01 0xfffffe01 0xfffffe01 0xfffffe01 0xfffffe01 0xfffffe01 0xfffffe01 0xfffffe01 0xfffffe01 0xfffffe01 0xfffffe01 0xfffffe01 0xfffffe01 0xfffffe01 0xfffffe01 0xfffffe01 0xfffffe01 0xfffffe01 0xfffffe01 0xfffffe01 0xfffffe01 0xfffffe01 0xfffffe01 0xfffffe01 0xfffffe01 0xfffffe01 0xfffffe01 0xfffffe01 0xfffffe01 0xfffffe01 0xfffffe01 0xfffffe01 0xfffffe01 0xfffffe01 0xfffffe01 0xfffffe01 0xfffffe01 0xfffffe01 0xfffffe01 0xfffffe01 0xfffffe01 0xfffffe01 0xfffffe01 0xfffffe01 0xfffffe01 0xfffffe01 0xfffffe01 0xfffffe01 0xfffffe01 0xfffffe01 0xfffffe01 0xfffffe01 0xfffffe01 0xfffffe01 0xfffffe01 0xfffffe01 0xfffffe01 0xfffffe01 0xfffffe01 0xfffffe01 0xfffffe01 0xfffffe01 0xfffffe01 0xfffffe01 0xfffffe01 0xfffffe01 0xfffffe01 0xfffffe01 0xfffffe01 0xfffffe01 0xfffffe01 0xfffffe01 0xfffffe01 0xfffffe01 0xfffffe01 0xfffffe01 0xfffffe01 0xfffffe01 0xfffffe01 0xfffffe01 0xfffffe01 0xfffffe01 0xfffffe01 0xfffffe01 0xfffffe01 0xfffffe01 0xfffffe01 0xfffffe01 0xfffffe01 0xfffffe01 0xfffffe01 0xfffffe01 0xfffffe01 0xfffffe01 0xfffffe01 0xfffffe01 0xfffffe01 0xfffffe01 0xfffffe01 0xfffffe01 0xfffffe01 0xfffffe01 0xfffffe01 0xfffffe01 0xfffffe01 0xfffffe01 0xfffffe01 0xfffffe01 0xfffffe01 0xfffffe01 0xfffffe01 0xfffffe01 0xfffffe01 0xfffffe01 0xfffffe01 0xfffffe01 0xfffffe01 0xfffffe01 0xfffffe01 0xfffffe01 0xfffffe01 0xfffffe01 0xfffffe01 0xfffffe01 0xfffffe01 0xfffffe01 0xfffffe01 0xfffffe01 0xfffffe01 0xfffffe01 0xfffffe01 0xfffffe01 0xfffffe01 0xfffffe01 0xfffffe01 0xfffffe01 0xfffffe01 0xfffffe01 0xfffffe01 0xfffffe01 0xfffffe01 0xfffffe01 0xfffffe01 0xfffffe01 0xfffffe01 0xfffffe01 0xfffffe01 0xfffffe01 0xfffffe01 0xfffffe01 0xfffffe01 0xfffffe01 0xfffffe01 0xfffffe01 0xfffffe01 0xfffffe01 0xfffffe01 0xfffffe01 0xfffffe01 0xfffffe01 0xfffffe01 0xfffffe01 0xfffffe01 0xfffffe01 0xfffffe01 0xfffffe01 0xfffffe01 0xfffffe01 0xfffffe01 0xfffffe01 0xfffffe01 0xfffffe01 0xfffffe01 0xfffffe01 0xfffffe01 0xfffffe01 0xfffffe01 0xfffffe01 0xfffffe01 0xfffffe01 0xfffffe01 0xfffffe01 0xfffffe01 0xfffffe01 0xfffffe01 0xfffffe01 0xfffffe01 0xfffffe01 0xfffffe01 0xfffffe01 0xfffffe01 0xfffffe01 0xfffffe01 0xfffffe01 0xfffffe01 0xfffffe01 0xfffffe01 0xfffffe01 0xfffffe01 0xfffffe01 0xfffffe01 0xfffffe01 0xfffffe01 0xfffffe01 0xfffffe01 0xfffffe01 0xfffffe01 0xfffffe01 0xfffffe01 0xfffffe01 0xfffffe01 0xfffffe01 0xfffffe01 0xfffffe01 0xfffffe01 0xfffffe01 0xfffffe01 0xfffffe01 0xfffffe01 0xfffffe01 0xfffffe01 0xfffffe01 0xfffffe01 0xfffffe01 0xfffffe01 0xfffffe01 0xfffffe01 0xfffffe01 0xfffffe01 0xfffffe01 0xfffffe01 0xfffffe01 0xfffffe01 0xfffffe01 0xfffffe01 0xfffffe01 0xfffffe01 0xfffffe01 0xfffffe01 0xfffffe01 0xfffffe01 0xfffffe01 0xfffffe01 0xfffffe01 0xfffffe01 0xfffffe01 0xfffffe01 0xfffffe01 0xfffffe01 0xfffffe01 0xfffffe01 0xfffffe01 0xfffffe01 0xfffffe01 0xfffffe01 0xfffffe01 0xfffffe01 0xfffffe01 0xfffffe01 0xfffffe01 0xfffffe01 0xfffffe01 0xfffffe01 0xfffffe01 0xfffffe01 0xfffffe01 0xfffffe01 0xfffffe01 0xfffffe01 0xfffffe01 0xfffffe01 0xfffffe01 0xfffffe01 0xfffffe01 0xfffffe01 0xfffffe01 0xfffffe01 0xfffffe01 0xfffffe01 0xfffffe01 0xfffffe01 0xfffffe01 0xfffffe01 0xfffffe01 0xfffffe01 0xfffffe01 0xfffffe01 0xfffffe01 0xfffffe01 0xfffffe01 0xfffffe01 0xfffffe01 0xfffffe01 0xfffffe01 0xfffffe01 0xfffffe01 0xfffffe01 0xfffffe01 0xfffffe01 0xfffffe01 0xfffffe01 0xfffffe01 0xfffffe01 0xfffffe01 0xfffffe01 0xfffffe01 0xfffffe01 0xfffffe01 0xfffffe01 0xfffffe01 0xfffffe01 0xfffffe01 0xfffffe01 0xfffffe01 0xfffffe01 0xfffffe01 0xfffffe01 0xfffffe01 0xfffffe01 0xfffffe01 0xfffffe01 0xfffffe01 0xfffffe01 0xfffffe01 0xfffffe01 0xfffffe01 0xfffffe01 0xfffffe01 0xfffffe01 0xfffffe01 0xfffffe01 0xfffffe01 0xfffffe01 0xfffffe01 0xfffffe01 0xfffffe01 0xfffffe01 0xfffffe01 0xfffffe01 0xfffffe01 0xfffffe01 0xfffffe01 0xfffffe01 0xfffffe01 0xfffffe01 0xfffffe01 0xfffffe01 0xfffffe01 0xfffffe01 0xfffffe01 0xfffffe01 0xfffffe01 0xfffffe01 0xfffffe01 0xfffffe01 0xfffffe01 0xfffffe01 0xfffffe01 0xfffffe01 0xfffffe01 0xfffffe01 0xfffffe01 0xfffffe01 0xfffffe01 0xfffffe01 0xfffffe01 0xfffffe01 0xfffffe01 0xfffffe01 0xfffffe01 0xfffffe01 0xfffffe01 0xfffffe01 0xfffffe01 0xfffffe01 0xfffffe01 0xfffffe01 0xfffffe01 0xfffffe01 0xfffffe01 0xfffffe01 0xfffffe01 0xfffffe01 0xfffffe01 0xfffffe01 0xfffffe01 0xfffffe01 0xfffffe01 0xfffffe01 0xfffffe01 0xfffffe01 0xfffffe01 0xfffffe01>;
			PS_Config_Lmt_FW_Rawdata_P = <0xf00 0xf00 0xf00 0xf00 0xf00 0xf00 0xf00 0xf00 0xf00 0xf00 0xf00 0xf00 0xf00 0xf00 0xf00 0xf00 0xf00 0xf00 0xf00 0xf00 0xf00 0xf00 0xf00 0xf00 0xf00 0xf00 0xf00 0xf00 0xf00 0xf00 0xf00 0xf00 0xf00 0xf00 0xf00 0xf00 0xf00 0xf00 0xf00 0xf00 0xf00 0xf00 0xf00 0xf00 0xf00 0xf00 0xf00 0xf00 0xf00 0xf00 0xf00 0xf00 0xf00 0xf00 0xf00 0xf00 0xf00 0xf00 0xf00 0xf00 0xf00 0xf00 0xf00 0xf00 0xf00 0xf00 0xf00 0xf00 0xf00 0xf00 0xf00 0xf00 0xf00 0xf00 0xf00 0xf00 0xf00 0xf00 0xf00 0xf00 0xf00 0xf00 0xf00 0xf00 0xf00 0xf00 0xf00 0xf00 0xf00 0xf00 0xf00 0xf00 0xf00 0xf00 0xf00 0xf00 0xf00 0xf00 0xf00 0xf00 0xf00 0xf00 0xf00 0xf00 0xf00 0xf00 0xf00 0xf00 0xf00 0xf00 0xf00 0xf00 0xf00 0xf00 0xf00 0xf00 0xf00 0xf00 0xf00 0xf00 0xf00 0xf00 0xf00 0xf00 0xf00 0xf00 0xf00 0xf00 0xf00 0xf00 0xf00 0xf00 0xf00 0xf00 0xf00 0xf00 0xf00 0xf00 0xf00 0xf00 0xf00 0xf00 0xf00 0xf00 0xf00 0xf00 0xf00 0xf00 0xf00 0xf00 0xf00 0xf00 0xf00 0xf00 0xf00 0xf00 0xf00 0xf00 0xf00 0xf00 0xf00 0xf00 0xf00 0xf00 0xf00 0xf00 0xf00 0xf00 0xf00 0xf00 0xf00 0xf00 0xf00 0xf00 0xf00 0xf00 0xf00 0xf00 0xf00 0xf00 0xf00 0xf00 0xf00 0xf00 0xf00 0xf00 0xf00 0xf00 0xf00 0xf00 0xf00 0xf00 0xf00 0xf00 0xf00 0xf00 0xf00 0xf00 0xf00 0xf00 0xf00 0xf00 0xf00 0xf00 0xf00 0xf00 0xf00 0xf00 0xf00 0xf00 0xf00 0xf00 0xf00 0xf00 0xf00 0xf00 0xf00 0xf00 0xf00 0xf00 0xf00 0xf00 0xf00 0xf00 0xf00 0xf00 0xf00 0xf00 0xf00 0xf00 0xf00 0xf00 0xf00 0xf00 0xf00 0xf00 0xf00 0xf00 0xf00 0xf00 0xf00 0xf00 0xf00 0xf00 0xf00 0xf00 0xf00 0xf00 0xf00 0xf00 0xf00 0xf00 0xf00 0xf00 0xf00 0xf00 0xf00 0xf00 0xf00 0xf00 0xf00 0xf00 0xf00 0xf00 0xf00 0xf00 0xf00 0xf00 0xf00 0xf00 0xf00 0xf00 0xf00 0xf00 0xf00 0xf00 0xf00 0xf00 0xf00 0xf00 0xf00 0xf00 0xf00 0xf00 0xf00 0xf00 0xf00 0xf00 0xf00 0xf00 0xf00 0xf00 0xf00 0xf00 0xf00 0xf00 0xf00 0xf00 0xf00 0xf00 0xf00 0xf00 0xf00 0xf00 0xf00 0xf00 0xf00 0xf00 0xf00 0xf00 0xf00 0xf00 0xf00 0xf00 0xf00 0xf00 0xf00 0xf00 0xf00 0xf00 0xf00 0xf00 0xf00 0xf00 0xf00 0xf00 0xf00 0xf00 0xf00 0xf00 0xf00 0xf00 0xf00 0xf00 0xf00 0xf00 0xf00 0xf00 0xf00 0xf00 0xf00 0xf00 0xf00 0xf00 0xf00 0xf00 0xf00 0xf00 0xf00 0xf00 0xf00 0xf00 0xf00 0xf00 0xf00 0xf00 0xf00 0xf00 0xf00 0xf00 0xf00 0xf00 0xf00 0xf00 0xf00 0xf00 0xf00 0xf00 0xf00 0xf00 0xf00 0xf00 0xf00 0xf00 0xf00 0xf00 0xf00 0xf00 0xf00 0xf00 0xf00 0xf00 0xf00 0xf00 0xf00 0xf00 0xf00 0xf00 0xf00 0xf00 0xf00 0xf00 0xf00 0xf00 0xf00 0xf00 0xf00 0xf00 0xf00 0xf00 0xf00 0xf00 0xf00 0xf00 0xf00 0xf00 0xf00 0xf00 0xf00 0xf00 0xf00 0xf00 0xf00 0xf00 0xf00 0xf00 0xf00 0xf00 0xf00 0xf00 0xf00 0xf00 0xf00 0xf00 0xf00 0xf00 0xf00 0xf00 0xf00 0xf00 0xf00 0xf00 0xf00 0xf00 0xf00 0xf00 0xf00 0xf00 0xf00 0xf00 0xf00 0xf00 0xf00 0xf00 0xf00 0xf00 0xf00 0xf00 0xf00 0xf00 0xf00 0xf00 0xf00 0xf00 0xf00 0xf00 0xf00 0xf00 0xf00 0xf00 0xf00 0xf00 0xf00 0xf00 0xf00 0xf00 0xf00 0xf00 0xf00 0xf00 0xf00 0xf00 0xf00 0xf00 0xf00 0xf00 0xf00 0xf00 0xf00 0xf00 0xf00 0xf00 0xf00 0xf00 0xf00 0xf00 0xf00 0xf00 0xf00 0xf00 0xf00 0xf00 0xf00 0xf00 0xf00 0xf00 0xf00 0xf00 0xf00 0xf00 0xf00 0xf00 0xf00 0xf00 0xf00 0xf00 0xf00 0xf00 0xf00 0xf00 0xf00 0xf00 0xf00 0xf00 0xf00 0xf00 0xf00 0xf00 0xf00 0xf00 0xf00 0xf00 0xf00 0xf00 0xf00 0xf00 0xf00 0xf00 0xf00 0xf00 0xf00 0xf00 0xf00 0xf00 0xf00 0xf00 0xf00 0xf00 0xf00 0xf00 0xf00 0xf00 0xf00 0xf00 0xf00 0xf00 0xf00 0xf00 0xf00 0xf00 0xf00 0xf00 0xf00 0xf00 0xf00 0xf00 0xf00 0xf00 0xf00 0xf00 0xf00 0xf00 0xf00 0xf00 0xf00 0xf00 0xf00 0xf00 0xf00 0xf00 0xf00 0xf00 0xf00 0xf00 0xf00 0xf00 0xf00 0xf00 0xf00 0xf00 0xf00 0xf00 0xf00 0xf00 0xf00 0xf00 0xf00 0xf00 0xf00 0xf00 0xf00 0xf00 0xf00 0xf00 0xf00 0xf00 0xf00 0xf00 0xf00 0xf00 0xf00 0xf00 0xf00 0xf00 0xf00 0xf00 0xf00 0xf00 0xf00 0xf00 0xf00 0xf00 0xf00 0xf00 0xf00 0xf00 0xf00 0xf00 0xf00 0xf00 0xf00 0xf00 0xf00 0xf00 0xf00 0xf00 0xf00 0xf00 0xf00 0xf00 0xf00 0xf00 0xf00 0xf00 0xf00 0xf00 0xf00 0xf00 0xf00 0xf00 0xf00 0xf00 0xf00 0xf00 0xf00 0xf00 0xf00 0xf00 0xf00 0xf00 0xf00>;
			PS_Config_Lmt_FW_Rawdata_N = <0xf0 0xf0 0xf0 0xf0 0xf0 0xf0 0xf0 0xf0 0xf0 0xf0 0xf0 0xf0 0xf0 0xf0 0xf0 0xf0 0xf0 0xf0 0xf0 0xf0 0xf0 0xf0 0xf0 0xf0 0xf0 0xf0 0xf0 0xf0 0xf0 0xf0 0xf0 0xf0 0xf0 0xf0 0xf0 0xf0 0xf0 0xf0 0xf0 0xf0 0xf0 0xf0 0xf0 0xf0 0xf0 0xf0 0xf0 0xf0 0xf0 0xf0 0xf0 0xf0 0xf0 0xf0 0xf0 0xf0 0xf0 0xf0 0xf0 0xf0 0xf0 0xf0 0xf0 0xf0 0xf0 0xf0 0xf0 0xf0 0xf0 0xf0 0xf0 0xf0 0xf0 0xf0 0xf0 0xf0 0xf0 0xf0 0xf0 0xf0 0xf0 0xf0 0xf0 0xf0 0xf0 0xf0 0xf0 0xf0 0xf0 0xf0 0xf0 0xf0 0xf0 0xf0 0xf0 0xf0 0xf0 0xf0 0xf0 0xf0 0xf0 0xf0 0xf0 0xf0 0xf0 0xf0 0xf0 0xf0 0xf0 0xf0 0xf0 0xf0 0xf0 0xf0 0xf0 0xf0 0xf0 0xf0 0xf0 0xf0 0xf0 0xf0 0xf0 0xf0 0xf0 0xf0 0xf0 0xf0 0xf0 0xf0 0xf0 0xf0 0xf0 0xf0 0xf0 0xf0 0xf0 0xf0 0xf0 0xf0 0xf0 0xf0 0xf0 0xf0 0xf0 0xf0 0xf0 0xf0 0xf0 0xf0 0xf0 0xf0 0xf0 0xf0 0xf0 0xf0 0xf0 0xf0 0xf0 0xf0 0xf0 0xf0 0xf0 0xf0 0xf0 0xf0 0xf0 0xf0 0xf0 0xf0 0xf0 0xf0 0xf0 0xf0 0xf0 0xf0 0xf0 0xf0 0xf0 0xf0 0xf0 0xf0 0xf0 0xf0 0xf0 0xf0 0xf0 0xf0 0xf0 0xf0 0xf0 0xf0 0xf0 0xf0 0xf0 0xf0 0xf0 0xf0 0xf0 0xf0 0xf0 0xf0 0xf0 0xf0 0xf0 0xf0 0xf0 0xf0 0xf0 0xf0 0xf0 0xf0 0xf0 0xf0 0xf0 0xf0 0xf0 0xf0 0xf0 0xf0 0xf0 0xf0 0xf0 0xf0 0xf0 0xf0 0xf0 0xf0 0xf0 0xf0 0xf0 0xf0 0xf0 0xf0 0xf0 0xf0 0xf0 0xf0 0xf0 0xf0 0xf0 0xf0 0xf0 0xf0 0xf0 0xf0 0xf0 0xf0 0xf0 0xf0 0xf0 0xf0 0xf0 0xf0 0xf0 0xf0 0xf0 0xf0 0xf0 0xf0 0xf0 0xf0 0xf0 0xf0 0xf0 0xf0 0xf0 0xf0 0xf0 0xf0 0xf0 0xf0 0xf0 0xf0 0xf0 0xf0 0xf0 0xf0 0xf0 0xf0 0xf0 0xf0 0xf0 0xf0 0xf0 0xf0 0xf0 0xf0 0xf0 0xf0 0xf0 0xf0 0xf0 0xf0 0xf0 0xf0 0xf0 0xf0 0xf0 0xf0 0xf0 0xf0 0xf0 0xf0 0xf0 0xf0 0xf0 0xf0 0xf0 0xf0 0xf0 0xf0 0xf0 0xf0 0xf0 0xf0 0xf0 0xf0 0xf0 0xf0 0xf0 0xf0 0xf0 0xf0 0xf0 0xf0 0xf0 0xf0 0xf0 0xf0 0xf0 0xf0 0xf0 0xf0 0xf0 0xf0 0xf0 0xf0 0xf0 0xf0 0xf0 0xf0 0xf0 0xf0 0xf0 0xf0 0xf0 0xf0 0xf0 0xf0 0xf0 0xf0 0xf0 0xf0 0xf0 0xf0 0xf0 0xf0 0xf0 0xf0 0xf0 0xf0 0xf0 0xf0 0xf0 0xf0 0xf0 0xf0 0xf0 0xf0 0xf0 0xf0 0xf0 0xf0 0xf0 0xf0 0xf0 0xf0 0xf0 0xf0 0xf0 0xf0 0xf0 0xf0 0xf0 0xf0 0xf0 0xf0 0xf0 0xf0 0xf0 0xf0 0xf0 0xf0 0xf0 0xf0 0xf0 0xf0 0xf0 0xf0 0xf0 0xf0 0xf0 0xf0 0xf0 0xf0 0xf0 0xf0 0xf0 0xf0 0xf0 0xf0 0xf0 0xf0 0xf0 0xf0 0xf0 0xf0 0xf0 0xf0 0xf0 0xf0 0xf0 0xf0 0xf0 0xf0 0xf0 0xf0 0xf0 0xf0 0xf0 0xf0 0xf0 0xf0 0xf0 0xf0 0xf0 0xf0 0xf0 0xf0 0xf0 0xf0 0xf0 0xf0 0xf0 0xf0 0xf0 0xf0 0xf0 0xf0 0xf0 0xf0 0xf0 0xf0 0xf0 0xf0 0xf0 0xf0 0xf0 0xf0 0xf0 0xf0 0xf0 0xf0 0xf0 0xf0 0xf0 0xf0 0xf0 0xf0 0xf0 0xf0 0xf0 0xf0 0xf0 0xf0 0xf0 0xf0 0xf0 0xf0 0xf0 0xf0 0xf0 0xf0 0xf0 0xf0 0xf0 0xf0 0xf0 0xf0 0xf0 0xf0 0xf0 0xf0 0xf0 0xf0 0xf0 0xf0 0xf0 0xf0 0xf0 0xf0 0xf0 0xf0 0xf0 0xf0 0xf0 0xf0 0xf0 0xf0 0xf0 0xf0 0xf0 0xf0 0xf0 0xf0 0xf0 0xf0 0xf0 0xf0 0xf0 0xf0 0xf0 0xf0 0xf0 0xf0 0xf0 0xf0 0xf0 0xf0 0xf0 0xf0 0xf0 0xf0 0xf0 0xf0 0xf0 0xf0 0xf0 0xf0 0xf0 0xf0 0xf0 0xf0 0xf0 0xf0 0xf0 0xf0 0xf0 0xf0 0xf0 0xf0 0xf0 0xf0 0xf0 0xf0 0xf0 0xf0 0xf0 0xf0 0xf0 0xf0 0xf0 0xf0 0xf0 0xf0 0xf0 0xf0 0xf0 0xf0 0xf0 0xf0 0xf0 0xf0 0xf0 0xf0 0xf0 0xf0 0xf0 0xf0 0xf0 0xf0 0xf0 0xf0 0xf0 0xf0 0xf0 0xf0 0xf0 0xf0 0xf0 0xf0 0xf0 0xf0 0xf0 0xf0 0xf0 0xf0 0xf0 0xf0 0xf0 0xf0 0xf0 0xf0 0xf0 0xf0 0xf0 0xf0 0xf0 0xf0 0xf0 0xf0 0xf0 0xf0 0xf0 0xf0 0xf0 0xf0 0xf0 0xf0 0xf0 0xf0 0xf0 0xf0 0xf0 0xf0 0xf0 0xf0 0xf0 0xf0 0xf0 0xf0 0xf0 0xf0 0xf0 0xf0 0xf0 0xf0 0xf0 0xf0 0xf0 0xf0 0xf0 0xf0 0xf0 0xf0 0xf0 0xf0 0xf0 0xf0 0xf0>;
			PS_Config_Lmt_FW_CC_P = <0x13a 0x13a 0x13a 0x13a 0x13a 0x13a 0x13a 0x13a 0x13a 0x13a 0x13a 0x13a 0x13a 0x13a 0x13a 0x13a 0x13a 0x13a 0x13a 0x13a 0x13a 0x13a 0x13a 0x13a 0x13a 0x13a 0x13a 0x13a 0x13a 0x13a 0x13a 0x13a 0x13a 0x13a 0x13a 0x13a 0x13a 0x13a 0x13a 0x13a 0x13a 0x13a 0x13a 0x13a 0x13a 0x13a 0x13a 0x13a 0x13a 0x13a 0x13a 0x13a 0x13a 0x13a 0x13a 0x13a 0x13a 0x13a 0x13a 0x13a 0x13a 0x13a 0x13a 0x13a 0x13a 0x13a 0x13a 0x13a 0x13a 0x13a 0x13a 0x13a 0x13a 0x13a 0x13a 0x13a 0x13a 0x13a 0x13a 0x13a 0x13a 0x13a 0x13a 0x13a 0x13a 0x13a 0x13a 0x13a 0x13a 0x13a 0x13a 0x13a 0x13a 0x13a 0x13a 0x13a 0x13a 0x13a 0x13a 0x13a 0x13a 0x13a 0x13a 0x13a 0x13a 0x13a 0x13a 0x13a 0x13a 0x13a 0x13a 0x13a 0x13a 0x13a 0x13a 0x13a 0x13a 0x13a 0x13a 0x13a 0x13a 0x13a 0x13a 0x13a 0x13a 0x13a 0x13a 0x13a 0x13a 0x13a 0x13a 0x13a 0x13a 0x13a 0x13a 0x13a 0x13a 0x13a 0x13a 0x13a 0x13a 0x13a 0x13a 0x13a 0x13a 0x13a 0x13a 0x13a 0x13a 0x13a 0x13a 0x13a 0x13a 0x13a 0x13a 0x13a 0x13a 0x13a 0x13a 0x13a 0x13a 0x13a 0x13a 0x13a 0x13a 0x13a 0x13a 0x13a 0x13a 0x13a 0x13a 0x13a 0x13a 0x13a 0x13a 0x13a 0x13a 0x13a 0x13a 0x13a 0x13a 0x13a 0x13a 0x13a 0x13a 0x13a 0x13a 0x13a 0x13a 0x13a 0x13a 0x13a 0x13a 0x13a 0x13a 0x13a 0x13a 0x13a 0x13a 0x13a 0x13a 0x13a 0x13a 0x13a 0x13a 0x13a 0x13a 0x13a 0x13a 0x13a 0x13a 0x13a 0x13a 0x13a 0x13a 0x13a 0x13a 0x13a 0x13a 0x13a 0x13a 0x13a 0x13a 0x13a 0x13a 0x13a 0x13a 0x13a 0x13a 0x13a 0x13a 0x13a 0x13a 0x13a 0x13a 0x13a 0x13a 0x13a 0x13a 0x13a 0x13a 0x13a 0x13a 0x13a 0x13a 0x13a 0x13a 0x13a 0x13a 0x13a 0x13a 0x13a 0x13a 0x13a 0x13a 0x13a 0x13a 0x13a 0x13a 0x13a 0x13a 0x13a 0x13a 0x13a 0x13a 0x13a 0x13a 0x13a 0x13a 0x13a 0x13a 0x13a 0x13a 0x13a 0x13a 0x13a 0x13a 0x13a 0x13a 0x13a 0x13a 0x13a 0x13a 0x13a 0x13a 0x13a 0x13a 0x13a 0x13a 0x13a 0x13a 0x13a 0x13a 0x13a 0x13a 0x13a 0x13a 0x13a 0x13a 0x13a 0x13a 0x13a 0x13a 0x13a 0x13a 0x13a 0x13a 0x13a 0x13a 0x13a 0x13a 0x13a 0x13a 0x13a 0x13a 0x13a 0x13a 0x13a 0x13a 0x13a 0x13a 0x13a 0x13a 0x13a 0x13a 0x13a 0x13a 0x13a 0x13a 0x13a 0x13a 0x13a 0x13a 0x13a 0x13a 0x13a 0x13a 0x13a 0x13a 0x13a 0x13a 0x13a 0x13a 0x13a 0x13a 0x13a 0x13a 0x13a 0x13a 0x13a 0x13a 0x13a 0x13a 0x13a 0x13a 0x13a 0x13a 0x13a 0x13a 0x13a 0x13a 0x13a 0x13a 0x13a 0x13a 0x13a 0x13a 0x13a 0x13a 0x13a 0x13a 0x13a 0x13a 0x13a 0x13a 0x13a 0x13a 0x13a 0x13a 0x13a 0x13a 0x13a 0x13a 0x13a 0x13a 0x13a 0x13a 0x13a 0x13a 0x13a 0x13a 0x13a 0x13a 0x13a 0x13a 0x13a 0x13a 0x13a 0x13a 0x13a 0x13a 0x13a 0x13a 0x13a 0x13a 0x13a 0x13a 0x13a 0x13a 0x13a 0x13a 0x13a 0x13a 0x13a 0x13a 0x13a 0x13a 0x13a 0x13a 0x13a 0x13a 0x13a 0x13a 0x13a 0x13a 0x13a 0x13a 0x13a 0x13a 0x13a 0x13a 0x13a 0x13a 0x13a 0x13a 0x13a 0x13a 0x13a 0x13a 0x13a 0x13a 0x13a 0x13a 0x13a 0x13a 0x13a 0x13a 0x13a 0x13a 0x13a 0x13a 0x13a 0x13a 0x13a 0x13a 0x13a 0x13a 0x13a 0x13a 0x13a 0x13a 0x13a 0x13a 0x13a 0x13a 0x13a 0x13a 0x13a 0x13a 0x13a 0x13a 0x13a 0x13a 0x13a 0x13a 0x13a 0x13a 0x13a 0x13a 0x13a 0x13a 0x13a 0x13a 0x13a 0x13a 0x13a 0x13a 0x13a 0x13a 0x13a 0x13a 0x13a 0x13a 0x13a 0x13a 0x13a 0x13a 0x13a 0x13a 0x13a 0x13a 0x13a 0x13a 0x13a 0x13a 0x13a 0x13a 0x13a 0x13a 0x13a 0x13a 0x13a 0x13a 0x13a 0x13a 0x13a 0x13a 0x13a 0x13a 0x13a 0x13a 0x13a 0x13a 0x13a 0x13a 0x13a 0x13a 0x13a 0x13a 0x13a 0x13a 0x13a 0x13a 0x13a 0x13a 0x13a 0x13a 0x13a 0x13a 0x13a 0x13a 0x13a 0x13a 0x13a 0x13a 0x13a 0x13a 0x13a 0x13a 0x13a 0x13a 0x13a 0x13a 0x13a 0x13a 0x13a 0x13a 0x13a 0x13a 0x13a 0x13a 0x13a 0x13a 0x13a 0x13a 0x13a 0x13a 0x13a 0x13a 0x13a 0x13a 0x13a 0x13a 0x13a 0x13a 0x13a 0x13a 0x13a 0x13a 0x13a 0x13a 0x13a 0x13a 0x13a 0x13a 0x13a 0x13a 0x13a 0x13a 0x13a 0x13a 0x13a 0x13a 0x13a 0x13a 0x13a 0x13a 0x13a 0x13a 0x13a 0x13a 0x13a 0x13a 0x13a 0x13a 0x13a 0x13a 0x13a 0x13a 0x13a 0x13a 0x13a 0x13a 0x13a 0x13a 0x13a 0x13a 0x13a 0x13a 0x13a 0x13a 0x13a 0x13a 0x13a 0x13a 0x13a 0x13a 0x13a 0x13a 0x13a 0x13a 0x13a 0x13a 0x13a 0x13a 0x13a 0x13a 0x13a 0x13a 0x13a 0x13a 0x13a 0x13a 0x13a 0x13a 0x13a 0x13a 0x13a 0x13a 0x13a 0x13a>;
			PS_Config_Lmt_FW_CC_N = <0x00 0x00 0x00 0x00 0x00 0x00 0x00 0x00 0x00 0x00 0x00 0x00 0x00 0x00 0x00 0x00 0x00 0x00 0x00 0x00 0x00 0x00 0x00 0x00 0x00 0x00 0x00 0x00 0x00 0x00 0x00 0x00 0x00 0x00 0x00 0x00 0x00 0x00 0x00 0x00 0x00 0x00 0x00 0x00 0x00 0x00 0x00 0x00 0x00 0x00 0x00 0x00 0x00 0x00 0x00 0x00 0x00 0x00 0x00 0x00 0x00 0x00 0x00 0x00 0x00 0x00 0x00 0x00 0x00 0x00 0x00 0x00 0x00 0x00 0x00 0x00 0x00 0x00 0x00 0x00 0x00 0x00 0x00 0x00 0x00 0x00 0x00 0x00 0x00 0x00 0x00 0x00 0x00 0x00 0x00 0x00 0x00 0x00 0x00 0x00 0x00 0x00 0x00 0x00 0x00 0x00 0x00 0x00 0x00 0x00 0x00 0x00 0x00 0x00 0x00 0x00 0x00 0x00 0x00 0x00 0x00 0x00 0x00 0x00 0x00 0x00 0x00 0x00 0x00 0x00 0x00 0x00 0x00 0x00 0x00 0x00 0x00 0x00 0x00 0x00 0x00 0x00 0x00 0x00 0x00 0x00 0x00 0x00 0x00 0x00 0x00 0x00 0x00 0x00 0x00 0x00 0x00 0x00 0x00 0x00 0x00 0x00 0x00 0x00 0x00 0x00 0x00 0x00 0x00 0x00 0x00 0x00 0x00 0x00 0x00 0x00 0x00 0x00 0x00 0x00 0x00 0x00 0x00 0x00 0x00 0x00 0x00 0x00 0x00 0x00 0x00 0x00 0x00 0x00 0x00 0x00 0x00 0x00 0x00 0x00 0x00 0x00 0x00 0x00 0x00 0x00 0x00 0x00 0x00 0x00 0x00 0x00 0x00 0x00 0x00 0x00 0x00 0x00 0x00 0x00 0x00 0x00 0x00 0x00 0x00 0x00 0x00 0x00 0x00 0x00 0x00 0x00 0x00 0x00 0x00 0x00 0x00 0x00 0x00 0x00 0x00 0x00 0x00 0x00 0x00 0x00 0x00 0x00 0x00 0x00 0x00 0x00 0x00 0x00 0x00 0x00 0x00 0x00 0x00 0x00 0x00 0x00 0x00 0x00 0x00 0x00 0x00 0x00 0x00 0x00 0x00 0x00 0x00 0x00 0x00 0x00 0x00 0x00 0x00 0x00 0x00 0x00 0x00 0x00 0x00 0x00 0x00 0x00 0x00 0x00 0x00 0x00 0x00 0x00 0x00 0x00 0x00 0x00 0x00 0x00 0x00 0x00 0x00 0x00 0x00 0x00 0x00 0x00 0x00 0x00 0x00 0x00 0x00 0x00 0x00 0x00 0x00 0x00 0x00 0x00 0x00 0x00 0x00 0x00 0x00 0x00 0x00 0x00 0x00 0x00 0x00 0x00 0x00 0x00 0x00 0x00 0x00 0x00 0x00 0x00 0x00 0x00 0x00 0x00 0x00 0x00 0x00 0x00 0x00 0x00 0x00 0x00 0x00 0x00 0x00 0x00 0x00 0x00 0x00 0x00 0x00 0x00 0x00 0x00 0x00 0x00 0x00 0x00 0x00 0x00 0x00 0x00 0x00 0x00 0x00 0x00 0x00 0x00 0x00 0x00 0x00 0x00 0x00 0x00 0x00 0x00 0x00 0x00 0x00 0x00 0x00 0x00 0x00 0x00 0x00 0x00 0x00 0x00 0x00 0x00 0x00 0x00 0x00 0x00 0x00 0x00 0x00 0x00 0x00 0x00 0x00 0x00 0x00 0x00 0x00 0x00 0x00 0x00 0x00 0x00 0x00 0x00 0x00 0x00 0x00 0x00 0x00 0x00 0x00 0x00 0x00 0x00 0x00 0x00 0x00 0x00 0x00 0x00 0x00 0x00 0x00 0x00 0x00 0x00 0x00 0x00 0x00 0x00 0x00 0x00 0x00 0x00 0x00 0x00 0x00 0x00 0x00 0x00 0x00 0x00 0x00 0x00 0x00 0x00 0x00 0x00 0x00 0x00 0x00 0x00 0x00 0x00 0x00 0x00 0x00 0x00 0x00 0x00 0x00 0x00 0x00 0x00 0x00 0x00 0x00 0x00 0x00 0x00 0x00 0x00 0x00 0x00 0x00 0x00 0x00 0x00 0x00 0x00 0x00 0x00 0x00 0x00 0x00 0x00 0x00 0x00 0x00 0x00 0x00 0x00 0x00 0x00 0x00 0x00 0x00 0x00 0x00 0x00 0x00 0x00 0x00 0x00 0x00 0x00 0x00 0x00 0x00 0x00 0x00 0x00 0x00 0x00 0x00 0x00 0x00 0x00 0x00 0x00 0x00 0x00 0x00 0x00 0x00 0x00 0x00 0x00 0x00 0x00 0x00 0x00 0x00 0x00 0x00 0x00 0x00 0x00 0x00 0x00 0x00 0x00 0x00 0x00 0x00 0x00 0x00 0x00 0x00 0x00 0x00 0x00 0x00 0x00 0x00 0x00 0x00 0x00 0x00 0x00 0x00 0x00 0x00 0x00 0x00 0x00 0x00 0x00 0x00 0x00 0x00 0x00 0x00 0x00 0x00 0x00 0x00 0x00 0x00 0x00 0x00 0x00 0x00 0x00 0x00 0x00 0x00 0x00 0x00 0x00 0x00 0x00 0x00 0x00 0x00 0x00 0x00 0x00 0x00 0x00 0x00 0x00 0x00 0x00 0x00 0x00 0x00 0x00 0x00 0x00 0x00 0x00 0x00 0x00 0x00 0x00 0x00 0x00 0x00 0x00 0x00 0x00 0x00 0x00 0x00 0x00 0x00 0x00 0x00 0x00 0x00 0x00 0x00>;
			PS_Config_Lmt_FW_Diff_P = <0x4b 0x4b 0x4b 0x4b 0x4b 0x4b 0x4b 0x4b 0x4b 0x4b 0x4b 0x4b 0x4b 0x4b 0x4b 0x4b 0x4b 0x4b 0x4b 0x4b 0x4b 0x4b 0x4b 0x4b 0x4b 0x4b 0x4b 0x4b 0x4b 0x4b 0x4b 0x4b 0x4b 0x4b 0x4b 0x4b 0x4b 0x4b 0x4b 0x4b 0x4b 0x4b 0x4b 0x4b 0x4b 0x4b 0x4b 0x4b 0x4b 0x4b 0x4b 0x4b 0x4b 0x4b 0x4b 0x4b 0x4b 0x4b 0x4b 0x4b 0x4b 0x4b 0x4b 0x4b 0x4b 0x4b 0x4b 0x4b 0x4b 0x4b 0x4b 0x4b 0x4b 0x4b 0x4b 0x4b 0x4b 0x4b 0x4b 0x4b 0x4b 0x4b 0x4b 0x4b 0x4b 0x4b 0x4b 0x4b 0x4b 0x4b 0x4b 0x4b 0x4b 0x4b 0x4b 0x4b 0x4b 0x4b 0x4b 0x4b 0x4b 0x4b 0x4b 0x4b 0x4b 0x4b 0x4b 0x4b 0x4b 0x4b 0x4b 0x4b 0x4b 0x4b 0x4b 0x4b 0x4b 0x4b 0x4b 0x4b 0x4b 0x4b 0x4b 0x4b 0x4b 0x4b 0x4b 0x4b 0x4b 0x4b 0x4b 0x4b 0x4b 0x4b 0x4b 0x4b 0x4b 0x4b 0x4b 0x4b 0x4b 0x4b 0x4b 0x4b 0x4b 0x4b 0x4b 0x4b 0x4b 0x4b 0x4b 0x4b 0x4b 0x4b 0x4b 0x4b 0x4b 0x4b 0x4b 0x4b 0x4b 0x4b 0x4b 0x4b 0x4b 0x4b 0x4b 0x4b 0x4b 0x4b 0x4b 0x4b 0x4b 0x4b 0x4b 0x4b 0x4b 0x4b 0x4b 0x4b 0x4b 0x4b 0x4b 0x4b 0x4b 0x4b 0x4b 0x4b 0x4b 0x4b 0x4b 0x4b 0x4b 0x4b 0x4b 0x4b 0x4b 0x4b 0x4b 0x4b 0x4b 0x4b 0x4b 0x4b 0x4b 0x4b 0x4b 0x4b 0x4b 0x4b 0x4b 0x4b 0x4b 0x4b 0x4b 0x4b 0x4b 0x4b 0x4b 0x4b 0x4b 0x4b 0x4b 0x4b 0x4b 0x4b 0x4b 0x4b 0x4b 0x4b 0x4b 0x4b 0x4b 0x4b 0x4b 0x4b 0x4b 0x4b 0x4b 0x4b 0x4b 0x4b 0x4b 0x4b 0x4b 0x4b 0x4b 0x4b 0x4b 0x4b 0x4b 0x4b 0x4b 0x4b 0x4b 0x4b 0x4b 0x4b 0x4b 0x4b 0x4b 0x4b 0x4b 0x4b 0x4b 0x4b 0x4b 0x4b 0x4b 0x4b 0x4b 0x4b 0x4b 0x4b 0x4b 0x4b 0x4b 0x4b 0x4b 0x4b 0x4b 0x4b 0x4b 0x4b 0x4b 0x4b 0x4b 0x4b 0x4b 0x4b 0x4b 0x4b 0x4b 0x4b 0x4b 0x4b 0x4b 0x4b 0x4b 0x4b 0x4b 0x4b 0x4b 0x4b 0x4b 0x4b 0x4b 0x4b 0x4b 0x4b 0x4b 0x4b 0x4b 0x4b 0x4b 0x4b 0x4b 0x4b 0x4b 0x4b 0x4b 0x4b 0x4b 0x4b 0x4b 0x4b 0x4b 0x4b 0x4b 0x4b 0x4b 0x4b 0x4b 0x4b 0x4b 0x4b 0x4b 0x4b 0x4b 0x4b 0x4b 0x4b 0x4b 0x4b 0x4b 0x4b 0x4b 0x4b 0x4b 0x4b 0x4b 0x4b 0x4b 0x4b 0x4b 0x4b 0x4b 0x4b 0x4b 0x4b 0x4b 0x4b 0x4b 0x4b 0x4b 0x4b 0x4b 0x4b 0x4b 0x4b 0x4b 0x4b 0x4b 0x4b 0x4b 0x4b 0x4b 0x4b 0x4b 0x4b 0x4b 0x4b 0x4b 0x4b 0x4b 0x4b 0x4b 0x4b 0x4b 0x4b 0x4b 0x4b 0x4b 0x4b 0x4b 0x4b 0x4b 0x4b 0x4b 0x4b 0x4b 0x4b 0x4b 0x4b 0x4b 0x4b 0x4b 0x4b 0x4b 0x4b 0x4b 0x4b 0x4b 0x4b 0x4b 0x4b 0x4b 0x4b 0x4b 0x4b 0x4b 0x4b 0x4b 0x4b 0x4b 0x4b 0x4b 0x4b 0x4b 0x4b 0x4b 0x4b 0x4b 0x4b 0x4b 0x4b 0x4b 0x4b 0x4b 0x4b 0x4b 0x4b 0x4b 0x4b 0x4b 0x4b 0x4b 0x4b 0x4b 0x4b 0x4b 0x4b 0x4b 0x4b 0x4b 0x4b 0x4b 0x4b 0x4b 0x4b 0x4b 0x4b 0x4b 0x4b 0x4b 0x4b 0x4b 0x4b 0x4b 0x4b 0x4b 0x4b 0x4b 0x4b 0x4b 0x4b 0x4b 0x4b 0x4b 0x4b 0x4b 0x4b 0x4b 0x4b 0x4b 0x4b 0x4b 0x4b 0x4b 0x4b 0x4b 0x4b 0x4b 0x4b 0x4b 0x4b 0x4b 0x4b 0x4b 0x4b 0x4b 0x4b 0x4b 0x4b 0x4b 0x4b 0x4b 0x4b 0x4b 0x4b 0x4b 0x4b 0x4b 0x4b 0x4b 0x4b 0x4b 0x4b 0x4b 0x4b 0x4b 0x4b 0x4b 0x4b 0x4b 0x4b 0x4b 0x4b 0x4b 0x4b 0x4b 0x4b 0x4b 0x4b 0x4b 0x4b 0x4b 0x4b 0x4b 0x4b 0x4b 0x4b 0x4b 0x4b 0x4b 0x4b 0x4b 0x4b 0x4b 0x4b 0x4b 0x4b 0x4b 0x4b 0x4b 0x4b 0x4b 0x4b 0x4b 0x4b 0x4b 0x4b 0x4b 0x4b 0x4b 0x4b 0x4b 0x4b 0x4b 0x4b 0x4b 0x4b 0x4b 0x4b 0x4b 0x4b 0x4b 0x4b 0x4b 0x4b 0x4b 0x4b 0x4b 0x4b 0x4b 0x4b 0x4b 0x4b 0x4b 0x4b 0x4b 0x4b 0x4b 0x4b 0x4b 0x4b 0x4b 0x4b 0x4b 0x4b 0x4b 0x4b 0x4b 0x4b 0x4b 0x4b 0x4b 0x4b 0x4b 0x4b 0x4b 0x4b 0x4b 0x4b 0x4b 0x4b 0x4b 0x4b 0x4b 0x4b 0x4b 0x4b 0x4b 0x4b 0x4b 0x4b 0x4b 0x4b 0x4b 0x4b 0x4b 0x4b 0x4b 0x4b 0x4b 0x4b 0x4b 0x4b 0x4b 0x4b 0x4b 0x4b 0x4b 0x4b 0x4b 0x4b 0x4b 0x4b 0x4b 0x4b 0x4b>;
			PS_Config_Lmt_FW_Diff_N = <0xffffffb5 0xffffffb5 0xffffffb5 0xffffffb5 0xffffffb5 0xffffffb5 0xffffffb5 0xffffffb5 0xffffffb5 0xffffffb5 0xffffffb5 0xffffffb5 0xffffffb5 0xffffffb5 0xffffffb5 0xffffffb5 0xffffffb5 0xffffffb5 0xffffffb5 0xffffffb5 0xffffffb5 0xffffffb5 0xffffffb5 0xffffffb5 0xffffffb5 0xffffffb5 0xffffffb5 0xffffffb5 0xffffffb5 0xffffffb5 0xffffffb5 0xffffffb5 0xffffffb5 0xffffffb5 0xffffffb5 0xffffffb5 0xffffffb5 0xffffffb5 0xffffffb5 0xffffffb5 0xffffffb5 0xffffffb5 0xffffffb5 0xffffffb5 0xffffffb5 0xffffffb5 0xffffffb5 0xffffffb5 0xffffffb5 0xffffffb5 0xffffffb5 0xffffffb5 0xffffffb5 0xffffffb5 0xffffffb5 0xffffffb5 0xffffffb5 0xffffffb5 0xffffffb5 0xffffffb5 0xffffffb5 0xffffffb5 0xffffffb5 0xffffffb5 0xffffffb5 0xffffffb5 0xffffffb5 0xffffffb5 0xffffffb5 0xffffffb5 0xffffffb5 0xffffffb5 0xffffffb5 0xffffffb5 0xffffffb5 0xffffffb5 0xffffffb5 0xffffffb5 0xffffffb5 0xffffffb5 0xffffffb5 0xffffffb5 0xffffffb5 0xffffffb5 0xffffffb5 0xffffffb5 0xffffffb5 0xffffffb5 0xffffffb5 0xffffffb5 0xffffffb5 0xffffffb5 0xffffffb5 0xffffffb5 0xffffffb5 0xffffffb5 0xffffffb5 0xffffffb5 0xffffffb5 0xffffffb5 0xffffffb5 0xffffffb5 0xffffffb5 0xffffffb5 0xffffffb5 0xffffffb5 0xffffffb5 0xffffffb5 0xffffffb5 0xffffffb5 0xffffffb5 0xffffffb5 0xffffffb5 0xffffffb5 0xffffffb5 0xffffffb5 0xffffffb5 0xffffffb5 0xffffffb5 0xffffffb5 0xffffffb5 0xffffffb5 0xffffffb5 0xffffffb5 0xffffffb5 0xffffffb5 0xffffffb5 0xffffffb5 0xffffffb5 0xffffffb5 0xffffffb5 0xffffffb5 0xffffffb5 0xffffffb5 0xffffffb5 0xffffffb5 0xffffffb5 0xffffffb5 0xffffffb5 0xffffffb5 0xffffffb5 0xffffffb5 0xffffffb5 0xffffffb5 0xffffffb5 0xffffffb5 0xffffffb5 0xffffffb5 0xffffffb5 0xffffffb5 0xffffffb5 0xffffffb5 0xffffffb5 0xffffffb5 0xffffffb5 0xffffffb5 0xffffffb5 0xffffffb5 0xffffffb5 0xffffffb5 0xffffffb5 0xffffffb5 0xffffffb5 0xffffffb5 0xffffffb5 0xffffffb5 0xffffffb5 0xffffffb5 0xffffffb5 0xffffffb5 0xffffffb5 0xffffffb5 0xffffffb5 0xffffffb5 0xffffffb5 0xffffffb5 0xffffffb5 0xffffffb5 0xffffffb5 0xffffffb5 0xffffffb5 0xffffffb5 0xffffffb5 0xffffffb5 0xffffffb5 0xffffffb5 0xffffffb5 0xffffffb5 0xffffffb5 0xffffffb5 0xffffffb5 0xffffffb5 0xffffffb5 0xffffffb5 0xffffffb5 0xffffffb5 0xffffffb5 0xffffffb5 0xffffffb5 0xffffffb5 0xffffffb5 0xffffffb5 0xffffffb5 0xffffffb5 0xffffffb5 0xffffffb5 0xffffffb5 0xffffffb5 0xffffffb5 0xffffffb5 0xffffffb5 0xffffffb5 0xffffffb5 0xffffffb5 0xffffffb5 0xffffffb5 0xffffffb5 0xffffffb5 0xffffffb5 0xffffffb5 0xffffffb5 0xffffffb5 0xffffffb5 0xffffffb5 0xffffffb5 0xffffffb5 0xffffffb5 0xffffffb5 0xffffffb5 0xffffffb5 0xffffffb5 0xffffffb5 0xffffffb5 0xffffffb5 0xffffffb5 0xffffffb5 0xffffffb5 0xffffffb5 0xffffffb5 0xffffffb5 0xffffffb5 0xffffffb5 0xffffffb5 0xffffffb5 0xffffffb5 0xffffffb5 0xffffffb5 0xffffffb5 0xffffffb5 0xffffffb5 0xffffffb5 0xffffffb5 0xffffffb5 0xffffffb5 0xffffffb5 0xffffffb5 0xffffffb5 0xffffffb5 0xffffffb5 0xffffffb5 0xffffffb5 0xffffffb5 0xffffffb5 0xffffffb5 0xffffffb5 0xffffffb5 0xffffffb5 0xffffffb5 0xffffffb5 0xffffffb5 0xffffffb5 0xffffffb5 0xffffffb5 0xffffffb5 0xffffffb5 0xffffffb5 0xffffffb5 0xffffffb5 0xffffffb5 0xffffffb5 0xffffffb5 0xffffffb5 0xffffffb5 0xffffffb5 0xffffffb5 0xffffffb5 0xffffffb5 0xffffffb5 0xffffffb5 0xffffffb5 0xffffffb5 0xffffffb5 0xffffffb5 0xffffffb5 0xffffffb5 0xffffffb5 0xffffffb5 0xffffffb5 0xffffffb5 0xffffffb5 0xffffffb5 0xffffffb5 0xffffffb5 0xffffffb5 0xffffffb5 0xffffffb5 0xffffffb5 0xffffffb5 0xffffffb5 0xffffffb5 0xffffffb5 0xffffffb5 0xffffffb5 0xffffffb5 0xffffffb5 0xffffffb5 0xffffffb5 0xffffffb5 0xffffffb5 0xffffffb5 0xffffffb5 0xffffffb5 0xffffffb5 0xffffffb5 0xffffffb5 0xffffffb5 0xffffffb5 0xffffffb5 0xffffffb5 0xffffffb5 0xffffffb5 0xffffffb5 0xffffffb5 0xffffffb5 0xffffffb5 0xffffffb5 0xffffffb5 0xffffffb5 0xffffffb5 0xffffffb5 0xffffffb5 0xffffffb5 0xffffffb5 0xffffffb5 0xffffffb5 0xffffffb5 0xffffffb5 0xffffffb5 0xffffffb5 0xffffffb5 0xffffffb5 0xffffffb5 0xffffffb5 0xffffffb5 0xffffffb5 0xffffffb5 0xffffffb5 0xffffffb5 0xffffffb5 0xffffffb5 0xffffffb5 0xffffffb5 0xffffffb5 0xffffffb5 0xffffffb5 0xffffffb5 0xffffffb5 0xffffffb5 0xffffffb5 0xffffffb5 0xffffffb5 0xffffffb5 0xffffffb5 0xffffffb5 0xffffffb5 0xffffffb5 0xffffffb5 0xffffffb5 0xffffffb5 0xffffffb5 0xffffffb5 0xffffffb5 0xffffffb5 0xffffffb5 0xffffffb5 0xffffffb5 0xffffffb5 0xffffffb5 0xffffffb5 0xffffffb5 0xffffffb5 0xffffffb5 0xffffffb5 0xffffffb5 0xffffffb5 0xffffffb5 0xffffffb5 0xffffffb5 0xffffffb5 0xffffffb5 0xffffffb5 0xffffffb5 0xffffffb5 0xffffffb5 0xffffffb5 0xffffffb5 0xffffffb5 0xffffffb5 0xffffffb5 0xffffffb5 0xffffffb5 0xffffffb5 0xffffffb5 0xffffffb5 0xffffffb5 0xffffffb5 0xffffffb5 0xffffffb5 0xffffffb5 0xffffffb5 0xffffffb5 0xffffffb5 0xffffffb5 0xffffffb5 0xffffffb5 0xffffffb5 0xffffffb5 0xffffffb5 0xffffffb5 0xffffffb5 0xffffffb5 0xffffffb5 0xffffffb5 0xffffffb5 0xffffffb5 0xffffffb5 0xffffffb5 0xffffffb5 0xffffffb5 0xffffffb5 0xffffffb5 0xffffffb5 0xffffffb5 0xffffffb5 0xffffffb5 0xffffffb5 0xffffffb5 0xffffffb5 0xffffffb5 0xffffffb5 0xffffffb5 0xffffffb5 0xffffffb5 0xffffffb5 0xffffffb5 0xffffffb5 0xffffffb5 0xffffffb5 0xffffffb5 0xffffffb5 0xffffffb5 0xffffffb5 0xffffffb5 0xffffffb5 0xffffffb5 0xffffffb5 0xffffffb5 0xffffffb5 0xffffffb5 0xffffffb5 0xffffffb5 0xffffffb5 0xffffffb5 0xffffffb5 0xffffffb5 0xffffffb5 0xffffffb5 0xffffffb5 0xffffffb5 0xffffffb5 0xffffffb5 0xffffffb5 0xffffffb5 0xffffffb5 0xffffffb5 0xffffffb5 0xffffffb5 0xffffffb5 0xffffffb5 0xffffffb5 0xffffffb5 0xffffffb5 0xffffffb5 0xffffffb5 0xffffffb5 0xffffffb5 0xffffffb5 0xffffffb5 0xffffffb5 0xffffffb5 0xffffffb5 0xffffffb5 0xffffffb5 0xffffffb5 0xffffffb5 0xffffffb5 0xffffffb5 0xffffffb5 0xffffffb5 0xffffffb5 0xffffffb5 0xffffffb5 0xffffffb5 0xffffffb5 0xffffffb5 0xffffffb5 0xffffffb5 0xffffffb5 0xffffffb5 0xffffffb5 0xffffffb5 0xffffffb5 0xffffffb5 0xffffffb5 0xffffffb5 0xffffffb5 0xffffffb5 0xffffffb5 0xffffffb5 0xffffffb5 0xffffffb5 0xffffffb5 0xffffffb5 0xffffffb5 0xffffffb5 0xffffffb5 0xffffffb5 0xffffffb5 0xffffffb5 0xffffffb5 0xffffffb5 0xffffffb5 0xffffffb5 0xffffffb5 0xffffffb5 0xffffffb5 0xffffffb5 0xffffffb5 0xffffffb5 0xffffffb5 0xffffffb5 0xffffffb5 0xffffffb5 0xffffffb5 0xffffffb5 0xffffffb5 0xffffffb5 0xffffffb5 0xffffffb5 0xffffffb5 0xffffffb5 0xffffffb5 0xffffffb5 0xffffffb5 0xffffffb5 0xffffffb5 0xffffffb5 0xffffffb5 0xffffffb5 0xffffffb5 0xffffffb5 0xffffffb5 0xffffffb5 0xffffffb5 0xffffffb5 0xffffffb5 0xffffffb5 0xffffffb5 0xffffffb5 0xffffffb5 0xffffffb5 0xffffffb5 0xffffffb5 0xffffffb5 0xffffffb5 0xffffffb5 0xffffffb5 0xffffffb5 0xffffffb5 0xffffffb5 0xffffffb5 0xffffffb5 0xffffffb5 0xffffffb5 0xffffffb5 0xffffffb5 0xffffffb5 0xffffffb5 0xffffffb5 0xffffffb5 0xffffffb5 0xffffffb5 0xffffffb5 0xffffffb5 0xffffffb5 0xffffffb5 0xffffffb5 0xffffffb5 0xffffffb5 0xffffffb5 0xffffffb5 0xffffffb5 0xffffffb5 0xffffffb5 0xffffffb5 0xffffffb5 0xffffffb5 0xffffffb5 0xffffffb5 0xffffffb5 0xffffffb5 0xffffffb5 0xffffffb5 0xffffffb5 0xffffffb5 0xffffffb5 0xffffffb5 0xffffffb5 0xffffffb5 0xffffffb5 0xffffffb5 0xffffffb5 0xffffffb5 0xffffffb5 0xffffffb5 0xffffffb5 0xffffffb5 0xffffffb5 0xffffffb5 0xffffffb5 0xffffffb5 0xffffffb5 0xffffffb5 0xffffffb5 0xffffffb5 0xffffffb5 0xffffffb5 0xffffffb5 0xffffffb5 0xffffffb5 0xffffffb5>;
			PS_Config_Diff_Test_Frame = <0x32>;
		};

		novatek-mp-criteria-594A@0 {
			#address-cells = <0x01>;
			#size-cells = <0x00>;
			compatible = "novatek-mp-criteria-594A";
			IC_X_CFG_SIZE = <0x10>;
			IC_Y_CFG_SIZE = <0x24>;
			IC_KEY_CFG_SIZE = <0x04>;
			X_Channel = <0x10>;
			Y_Channel = <0x24>;
			AIN_X = <0x00 0x01 0x02 0x03 0x04 0x05 0x06 0x07 0x08 0x09 0x0a 0x0b 0x0c 0x0d 0x0e 0x0f>;
			AIN_Y = <0x00 0x01 0x02 0x03 0x04 0x05 0x06 0x07 0x08 0x09 0x0a 0x0b 0x0c 0x0d 0x0e 0x0f 0x10 0x11 0x12 0x13 0x14 0x15 0x16 0x17 0x18 0x19 0x1a 0x1b 0x1c 0x1d 0x1e 0x1f 0x20 0x21 0x22 0x23>;
			AIN_KEY = <0x00 0x01 0x02 0xff>;
			PS_Config_Lmt_Short_Rawdata_P = <0x36b8 0x36b8 0x36b8 0x36b8 0x36b8 0x36b8 0x36b8 0x36b8 0x36b8 0x36b8 0x36b8 0x36b8 0x36b8 0x36b8 0x36b8 0x36b8 0x36b8 0x36b8 0x36b8 0x36b8 0x36b8 0x36b8 0x36b8 0x36b8 0x36b8 0x36b8 0x36b8 0x36b8 0x36b8 0x36b8 0x36b8 0x36b8 0x36b8 0x36b8 0x36b8 0x36b8 0x36b8 0x36b8 0x36b8 0x36b8 0x36b8 0x36b8 0x36b8 0x36b8 0x36b8 0x36b8 0x36b8 0x36b8 0x36b8 0x36b8 0x36b8 0x36b8 0x36b8 0x36b8 0x36b8 0x36b8 0x36b8 0x36b8 0x36b8 0x36b8 0x36b8 0x36b8 0x36b8 0x36b8 0x36b8 0x36b8 0x36b8 0x36b8 0x36b8 0x36b8 0x36b8 0x36b8 0x36b8 0x36b8 0x36b8 0x36b8 0x36b8 0x36b8 0x36b8 0x36b8 0x36b8 0x36b8 0x36b8 0x36b8 0x36b8 0x36b8 0x36b8 0x36b8 0x36b8 0x36b8 0x36b8 0x36b8 0x36b8 0x36b8 0x36b8 0x36b8 0x36b8 0x36b8 0x36b8 0x36b8 0x36b8 0x36b8 0x36b8 0x36b8 0x36b8 0x36b8 0x36b8 0x36b8 0x36b8 0x36b8 0x36b8 0x36b8 0x36b8 0x36b8 0x36b8 0x36b8 0x36b8 0x36b8 0x36b8 0x36b8 0x36b8 0x36b8 0x36b8 0x36b8 0x36b8 0x36b8 0x36b8 0x36b8 0x36b8 0x36b8 0x36b8 0x36b8 0x36b8 0x36b8 0x36b8 0x36b8 0x36b8 0x36b8 0x36b8 0x36b8 0x36b8 0x36b8 0x36b8 0x36b8 0x36b8 0x36b8 0x36b8 0x36b8 0x36b8 0x36b8 0x36b8 0x36b8 0x36b8 0x36b8 0x36b8 0x36b8 0x36b8 0x36b8 0x36b8 0x36b8 0x36b8 0x36b8 0x36b8 0x36b8 0x36b8 0x36b8 0x36b8 0x36b8 0x36b8 0x36b8 0x36b8 0x36b8 0x36b8 0x36b8 0x36b8 0x36b8 0x36b8 0x36b8 0x36b8 0x36b8 0x36b8 0x36b8 0x36b8 0x36b8 0x36b8 0x36b8 0x36b8 0x36b8 0x36b8 0x36b8 0x36b8 0x36b8 0x36b8 0x36b8 0x36b8 0x36b8 0x36b8 0x36b8 0x36b8 0x36b8 0x36b8 0x36b8 0x36b8 0x36b8 0x36b8 0x36b8 0x36b8 0x36b8 0x36b8 0x36b8 0x36b8 0x36b8 0x36b8 0x36b8 0x36b8 0x36b8 0x36b8 0x36b8 0x36b8 0x36b8 0x36b8 0x36b8 0x36b8 0x36b8 0x36b8 0x36b8 0x36b8 0x36b8 0x36b8 0x36b8 0x36b8 0x36b8 0x36b8 0x36b8 0x36b8 0x36b8 0x36b8 0x36b8 0x36b8 0x36b8 0x36b8 0x36b8 0x36b8 0x36b8 0x36b8 0x36b8 0x36b8 0x36b8 0x36b8 0x36b8 0x36b8 0x36b8 0x36b8 0x36b8 0x36b8 0x36b8 0x36b8 0x36b8 0x36b8 0x36b8 0x36b8 0x36b8 0x36b8 0x36b8 0x36b8 0x36b8 0x36b8 0x36b8 0x36b8 0x36b8 0x36b8 0x36b8 0x36b8 0x36b8 0x36b8 0x36b8 0x36b8 0x36b8 0x36b8 0x36b8 0x36b8 0x36b8 0x36b8 0x36b8 0x36b8 0x36b8 0x36b8 0x36b8 0x36b8 0x36b8 0x36b8 0x36b8 0x36b8 0x36b8 0x36b8 0x36b8 0x36b8 0x36b8 0x36b8 0x36b8 0x36b8 0x36b8 0x36b8 0x36b8 0x36b8 0x36b8 0x36b8 0x36b8 0x36b8 0x36b8 0x36b8 0x36b8 0x36b8 0x36b8 0x36b8 0x36b8 0x36b8 0x36b8 0x36b8 0x36b8 0x36b8 0x36b8 0x36b8 0x36b8 0x36b8 0x36b8 0x36b8 0x36b8 0x36b8 0x36b8 0x36b8 0x36b8 0x36b8 0x36b8 0x36b8 0x36b8 0x36b8 0x36b8 0x36b8 0x36b8 0x36b8 0x36b8 0x36b8 0x36b8 0x36b8 0x36b8 0x36b8 0x36b8 0x36b8 0x36b8 0x36b8 0x36b8 0x36b8 0x36b8 0x36b8 0x36b8 0x36b8 0x36b8 0x36b8 0x36b8 0x36b8 0x36b8 0x36b8 0x36b8 0x36b8 0x36b8 0x36b8 0x36b8 0x36b8 0x36b8 0x36b8 0x36b8 0x36b8 0x36b8 0x36b8 0x36b8 0x36b8 0x36b8 0x36b8 0x36b8 0x36b8 0x36b8 0x36b8 0x36b8 0x36b8 0x36b8 0x36b8 0x36b8 0x36b8 0x36b8 0x36b8 0x36b8 0x36b8 0x36b8 0x36b8 0x36b8 0x36b8 0x36b8 0x36b8 0x36b8 0x36b8 0x36b8 0x36b8 0x36b8 0x36b8 0x36b8 0x36b8 0x36b8 0x36b8 0x36b8 0x36b8 0x36b8 0x36b8 0x36b8 0x36b8 0x36b8 0x36b8 0x36b8 0x36b8 0x36b8 0x36b8 0x36b8 0x36b8 0x36b8 0x36b8 0x36b8 0x36b8 0x36b8 0x36b8 0x36b8 0x36b8 0x36b8 0x36b8 0x36b8 0x36b8 0x36b8 0x36b8 0x36b8 0x36b8 0x36b8 0x36b8 0x36b8 0x36b8 0x36b8 0x36b8 0x36b8 0x36b8 0x36b8 0x36b8 0x36b8 0x36b8 0x36b8 0x36b8 0x36b8 0x36b8 0x36b8 0x36b8 0x36b8 0x36b8 0x36b8 0x36b8 0x36b8 0x36b8 0x36b8 0x36b8 0x36b8 0x36b8 0x36b8 0x36b8 0x36b8 0x36b8 0x36b8 0x36b8 0x36b8 0x36b8 0x36b8 0x36b8 0x36b8 0x36b8 0x36b8 0x36b8 0x36b8 0x36b8 0x36b8 0x36b8 0x36b8 0x36b8 0x36b8 0x36b8 0x36b8 0x36b8 0x36b8 0x36b8 0x36b8 0x36b8 0x36b8 0x36b8 0x36b8 0x36b8 0x36b8 0x36b8 0x36b8 0x36b8 0x36b8 0x36b8 0x36b8 0x36b8 0x36b8 0x36b8 0x36b8 0x36b8 0x36b8 0x36b8 0x36b8 0x36b8 0x36b8 0x36b8 0x36b8 0x36b8 0x36b8 0x36b8 0x36b8 0x36b8 0x36b8 0x36b8 0x36b8 0x36b8 0x36b8 0x36b8 0x36b8 0x36b8 0x36b8 0x36b8 0x36b8 0x36b8 0x36b8 0x36b8 0x36b8 0x36b8 0x36b8 0x36b8 0x36b8 0x36b8 0x36b8 0x36b8 0x36b8 0x36b8 0x36b8 0x36b8 0x36b8 0x36b8 0x36b8 0x36b8 0x36b8 0x36b8 0x36b8 0x36b8 0x36b8 0x36b8 0x36b8 0x36b8 0x36b8 0x36b8 0x36b8 0x36b8 0x36b8 0x36b8 0x36b8 0x36b8 0x36b8 0x36b8 0x36b8 0x36b8 0x36b8 0x36b8 0x36b8 0x36b8 0x36b8 0x36b8>;
			PS_Config_Lmt_Short_Rawdata_N = <0x2710 0x2710 0x2710 0x2710 0x2710 0x2710 0x2710 0x2710 0x2710 0x2710 0x2710 0x2710 0x2710 0x2710 0x2710 0x2710 0x2710 0x2710 0x2710 0x2710 0x2710 0x2710 0x2710 0x2710 0x2710 0x2710 0x2710 0x2710 0x2710 0x2710 0x2710 0x2710 0x2710 0x2710 0x2710 0x2710 0x2710 0x2710 0x2710 0x2710 0x2710 0x2710 0x2710 0x2710 0x2710 0x2710 0x2710 0x2710 0x2710 0x2710 0x2710 0x2710 0x2710 0x2710 0x2710 0x2710 0x2710 0x2710 0x2710 0x2710 0x2710 0x2710 0x2710 0x2710 0x2710 0x2710 0x2710 0x2710 0x2710 0x2710 0x2710 0x2710 0x2710 0x2710 0x2710 0x2710 0x2710 0x2710 0x2710 0x2710 0x2710 0x2710 0x2710 0x2710 0x2710 0x2710 0x2710 0x2710 0x2710 0x2710 0x2710 0x2710 0x2710 0x2710 0x2710 0x2710 0x2710 0x2710 0x2710 0x2710 0x2710 0x2710 0x2710 0x2710 0x2710 0x2710 0x2710 0x2710 0x2710 0x2710 0x2710 0x2710 0x2710 0x2710 0x2710 0x2710 0x2710 0x2710 0x2710 0x2710 0x2710 0x2710 0x2710 0x2710 0x2710 0x2710 0x2710 0x2710 0x2710 0x2710 0x2710 0x2710 0x2710 0x2710 0x2710 0x2710 0x2710 0x2710 0x2710 0x2710 0x2710 0x2710 0x2710 0x2710 0x2710 0x2710 0x2710 0x2710 0x2710 0x2710 0x2710 0x2710 0x2710 0x2710 0x2710 0x2710 0x2710 0x2710 0x2710 0x2710 0x2710 0x2710 0x2710 0x2710 0x2710 0x2710 0x2710 0x2710 0x2710 0x2710 0x2710 0x2710 0x2710 0x2710 0x2710 0x2710 0x2710 0x2710 0x2710 0x2710 0x2710 0x2710 0x2710 0x2710 0x2710 0x2710 0x2710 0x2710 0x2710 0x2710 0x2710 0x2710 0x2710 0x2710 0x2710 0x2710 0x2710 0x2710 0x2710 0x2710 0x2710 0x2710 0x2710 0x2710 0x2710 0x2710 0x2710 0x2710 0x2710 0x2710 0x2710 0x2710 0x2710 0x2710 0x2710 0x2710 0x2710 0x2710 0x2710 0x2710 0x2710 0x2710 0x2710 0x2710 0x2710 0x2710 0x2710 0x2710 0x2710 0x2710 0x2710 0x2710 0x2710 0x2710 0x2710 0x2710 0x2710 0x2710 0x2710 0x2710 0x2710 0x2710 0x2710 0x2710 0x2710 0x2710 0x2710 0x2710 0x2710 0x2710 0x2710 0x2710 0x2710 0x2710 0x2710 0x2710 0x2710 0x2710 0x2710 0x2710 0x2710 0x2710 0x2710 0x2710 0x2710 0x2710 0x2710 0x2710 0x2710 0x2710 0x2710 0x2710 0x2710 0x2710 0x2710 0x2710 0x2710 0x2710 0x2710 0x2710 0x2710 0x2710 0x2710 0x2710 0x2710 0x2710 0x2710 0x2710 0x2710 0x2710 0x2710 0x2710 0x2710 0x2710 0x2710 0x2710 0x2710 0x2710 0x2710 0x2710 0x2710 0x2710 0x2710 0x2710 0x2710 0x2710 0x2710 0x2710 0x2710 0x2710 0x2710 0x2710 0x2710 0x2710 0x2710 0x2710 0x2710 0x2710 0x2710 0x2710 0x2710 0x2710 0x2710 0x2710 0x2710 0x2710 0x2710 0x2710 0x2710 0x2710 0x2710 0x2710 0x2710 0x2710 0x2710 0x2710 0x2710 0x2710 0x2710 0x2710 0x2710 0x2710 0x2710 0x2710 0x2710 0x2710 0x2710 0x2710 0x2710 0x2710 0x2710 0x2710 0x2710 0x2710 0x2710 0x2710 0x2710 0x2710 0x2710 0x2710 0x2710 0x2710 0x2710 0x2710 0x2710 0x2710 0x2710 0x2710 0x2710 0x2710 0x2710 0x2710 0x2710 0x2710 0x2710 0x2710 0x2710 0x2710 0x2710 0x2710 0x2710 0x2710 0x2710 0x2710 0x2710 0x2710 0x2710 0x2710 0x2710 0x2710 0x2710 0x2710 0x2710 0x2710 0x2710 0x2710 0x2710 0x2710 0x2710 0x2710 0x2710 0x2710 0x2710 0x2710 0x2710 0x2710 0x2710 0x2710 0x2710 0x2710 0x2710 0x2710 0x2710 0x2710 0x2710 0x2710 0x2710 0x2710 0x2710 0x2710 0x2710 0x2710 0x2710 0x2710 0x2710 0x2710 0x2710 0x2710 0x2710 0x2710 0x2710 0x2710 0x2710 0x2710 0x2710 0x2710 0x2710 0x2710 0x2710 0x2710 0x2710 0x2710 0x2710 0x2710 0x2710 0x2710 0x2710 0x2710 0x2710 0x2710 0x2710 0x2710 0x2710 0x2710 0x2710 0x2710 0x2710 0x2710 0x2710 0x2710 0x2710 0x2710 0x2710 0x2710 0x2710 0x2710 0x2710 0x2710 0x2710 0x2710 0x2710 0x2710 0x2710 0x2710 0x2710 0x2710 0x2710 0x2710 0x2710 0x2710 0x2710 0x2710 0x2710 0x2710 0x2710 0x2710 0x2710 0x2710 0x2710 0x2710 0x2710 0x2710 0x2710 0x2710 0x2710 0x2710 0x2710 0x2710 0x2710 0x2710 0x2710 0x2710 0x2710 0x2710 0x2710 0x2710 0x2710 0x2710 0x2710 0x2710 0x2710 0x2710 0x2710 0x2710 0x2710 0x2710 0x2710 0x2710 0x2710 0x2710 0x2710 0x2710 0x2710 0x2710 0x2710 0x2710 0x2710 0x2710 0x2710 0x2710 0x2710 0x2710 0x2710 0x2710 0x2710 0x2710 0x2710 0x2710 0x2710 0x2710 0x2710 0x2710 0x2710 0x2710 0x2710 0x2710 0x2710 0x2710 0x2710 0x2710 0x2710 0x2710 0x2710 0x2710 0x2710 0x2710 0x2710 0x2710 0x2710 0x2710 0x2710 0x2710 0x2710 0x2710 0x2710 0x2710 0x2710 0x2710 0x2710 0x2710 0x2710 0x2710 0x2710 0x2710 0x2710 0x2710 0x2710 0x2710 0x2710>;
			PS_Config_Lmt_Open_Rawdata_P = <0x1400 0x1400 0x1400 0x1400 0x1400 0x1400 0x1400 0x1400 0x1400 0x1400 0x1400 0x1400 0x1400 0x1400 0x1400 0x1400 0x1400 0x1400 0x1400 0x1400 0x1400 0x1400 0x1400 0x1400 0x1400 0x1400 0x1400 0x1400 0x1400 0x1400 0x1400 0x1400 0x1400 0x1400 0x1400 0x1400 0x1400 0x1400 0x1400 0x1400 0x1400 0x1400 0x1400 0x1400 0x1400 0x1400 0x1400 0x1400 0x1400 0x1400 0x1400 0x1400 0x1400 0x1400 0x1400 0x1400 0x1400 0x1400 0x1400 0x1400 0x1400 0x1400 0x1400 0x1400 0x1400 0x1400 0x1400 0x1400 0x1400 0x1400 0x1400 0x1400 0x1400 0x1400 0x1400 0x1400 0x1400 0x1400 0x1400 0x1400 0x1400 0x1400 0x1400 0x1400 0x1400 0x1400 0x1400 0x1400 0x1400 0x1400 0x1400 0x1400 0x1400 0x1400 0x1400 0x1400 0x1400 0x1400 0x1400 0x1400 0x1400 0x1400 0x1400 0x1400 0x1400 0x1400 0x1400 0x1400 0x1400 0x1400 0x1400 0x1400 0x1400 0x1400 0x1400 0x1400 0x1400 0x1400 0x1400 0x1400 0x1400 0x1400 0x1400 0x1400 0x1400 0x1400 0x1400 0x1400 0x1400 0x1400 0x1400 0x1400 0x1400 0x1400 0x1400 0x1400 0x1400 0x1400 0x1400 0x1400 0x1400 0x1400 0x1400 0x1400 0x1400 0x1400 0x1400 0x1400 0x1400 0x1400 0x1400 0x1400 0x1400 0x1400 0x1400 0x1400 0x1400 0x1400 0x1400 0x1400 0x1400 0x1400 0x1400 0x1400 0x1400 0x1400 0x1400 0x1400 0x1400 0x1400 0x1400 0x1400 0x1400 0x1400 0x1400 0x1400 0x1400 0x1400 0x1400 0x1400 0x1400 0x1400 0x1400 0x1400 0x1400 0x1400 0x1400 0x1400 0x1400 0x1400 0x1400 0x1400 0x1400 0x1400 0x1400 0x1400 0x1400 0x1400 0x1400 0x1400 0x1400 0x1400 0x1400 0x1400 0x1400 0x1400 0x1400 0x1400 0x1400 0x1400 0x1400 0x1400 0x1400 0x1400 0x1400 0x1400 0x1400 0x1400 0x1400 0x1400 0x1400 0x1400 0x1400 0x1400 0x1400 0x1400 0x1400 0x1400 0x1400 0x1400 0x1400 0x1400 0x1400 0x1400 0x1400 0x1400 0x1400 0x1400 0x1400 0x1400 0x1400 0x1400 0x1400 0x1400 0x1400 0x1400 0x1400 0x1400 0x1400 0x1400 0x1400 0x1400 0x1400 0x1400 0x1400 0x1400 0x1400 0x1400 0x1400 0x1400 0x1400 0x1400 0x1400 0x1400 0x1400 0x1400 0x1400 0x1400 0x1400 0x1400 0x1400 0x1400 0x1400 0x1400 0x1400 0x1400 0x1400 0x1400 0x1400 0x1400 0x1400 0x1400 0x1400 0x1400 0x1400 0x1400 0x1400 0x1400 0x1400 0x1400 0x1400 0x1400 0x1400 0x1400 0x1400 0x1400 0x1400 0x1400 0x1400 0x1400 0x1400 0x1400 0x1400 0x1400 0x1400 0x1400 0x1400 0x1400 0x1400 0x1400 0x1400 0x1400 0x1400 0x1400 0x1400 0x1400 0x1400 0x1400 0x1400 0x1400 0x1400 0x1400 0x1400 0x1400 0x1400 0x1400 0x1400 0x1400 0x1400 0x1400 0x1400 0x1400 0x1400 0x1400 0x1400 0x1400 0x1400 0x1400 0x1400 0x1400 0x1400 0x1400 0x1400 0x1400 0x1400 0x1400 0x1400 0x1400 0x1400 0x1400 0x1400 0x1400 0x1400 0x1400 0x1400 0x1400 0x1400 0x1400 0x1400 0x1400 0x1400 0x1400 0x1400 0x1400 0x1400 0x1400 0x1400 0x1400 0x1400 0x1400 0x1400 0x1400 0x1400 0x1400 0x1400 0x1400 0x1400 0x1400 0x1400 0x1400 0x1400 0x1400 0x1400 0x1400 0x1400 0x1400 0x1400 0x1400 0x1400 0x1400 0x1400 0x1400 0x1400 0x1400 0x1400 0x1400 0x1400 0x1400 0x1400 0x1400 0x1400 0x1400 0x1400 0x1400 0x1400 0x1400 0x1400 0x1400 0x1400 0x1400 0x1400 0x1400 0x1400 0x1400 0x1400 0x1400 0x1400 0x1400 0x1400 0x1400 0x1400 0x1400 0x1400 0x1400 0x1400 0x1400 0x1400 0x1400 0x1400 0x1400 0x1400 0x1400 0x1400 0x1400 0x1400 0x1400 0x1400 0x1400 0x1400 0x1400 0x1400 0x1400 0x1400 0x1400 0x1400 0x1400 0x1400 0x1400 0x1400 0x1400 0x1400 0x1400 0x1400 0x1400 0x1400 0x1400 0x1400 0x1400 0x1400 0x1400 0x1400 0x1400 0x1400 0x1400 0x1400 0x1400 0x1400 0x1400 0x1400 0x1400 0x1400 0x1400 0x1400 0x1400 0x1400 0x1400 0x1400 0x1400 0x1400 0x1400 0x1400 0x1400 0x1400 0x1400 0x1400 0x1400 0x1400 0x1400 0x1400 0x1400 0x1400 0x1400 0x1400 0x1400 0x1400 0x1400 0x1400 0x1400 0x1400 0x1400 0x1400 0x1400 0x1400 0x1400 0x1400 0x1400 0x1400 0x1400 0x1400 0x1400 0x1400 0x1400 0x1400 0x1400 0x1400 0x1400 0x1400 0x1400 0x1400 0x1400 0x1400 0x1400 0x1400 0x1400 0x1400 0x1400 0x1400 0x1400 0x1400 0x1400 0x1400 0x1400 0x1400 0x1400 0x1400 0x1400 0x1400 0x1400 0x1400 0x1400 0x1400 0x1400 0x1400 0x1400 0x1400 0x1400 0x1400 0x1400 0x1400 0x1400 0x1400 0x1400 0x1400 0x1400 0x1400 0x1400 0x1400 0x1400 0x1400 0x1400 0x1400 0x1400 0x1400 0x1400 0x1400 0x1400 0x1400 0x1400 0x1400 0x1400 0x1400 0x1400 0x1400 0x1400 0x1400 0x1400 0x1400 0x1400 0x1400>;
			PS_Config_Lmt_Open_Rawdata_N = <0xfffffe01 0xfffffe01 0xfffffe01 0xfffffe01 0xfffffe01 0xfffffe01 0xfffffe01 0xfffffe01 0xfffffe01 0xfffffe01 0xfffffe01 0xfffffe01 0xfffffe01 0xfffffe01 0xfffffe01 0xfffffe01 0xfffffe01 0xfffffe01 0xfffffe01 0xfffffe01 0xfffffe01 0xfffffe01 0xfffffe01 0xfffffe01 0xfffffe01 0xfffffe01 0xfffffe01 0xfffffe01 0xfffffe01 0xfffffe01 0xfffffe01 0xfffffe01 0xfffffe01 0xfffffe01 0xfffffe01 0xfffffe01 0xfffffe01 0xfffffe01 0xfffffe01 0xfffffe01 0xfffffe01 0xfffffe01 0xfffffe01 0xfffffe01 0xfffffe01 0xfffffe01 0xfffffe01 0xfffffe01 0xfffffe01 0xfffffe01 0xfffffe01 0xfffffe01 0xfffffe01 0xfffffe01 0xfffffe01 0xfffffe01 0xfffffe01 0xfffffe01 0xfffffe01 0xfffffe01 0xfffffe01 0xfffffe01 0xfffffe01 0xfffffe01 0xfffffe01 0xfffffe01 0xfffffe01 0xfffffe01 0xfffffe01 0xfffffe01 0xfffffe01 0xfffffe01 0xfffffe01 0xfffffe01 0xfffffe01 0xfffffe01 0xfffffe01 0xfffffe01 0xfffffe01 0xfffffe01 0xfffffe01 0xfffffe01 0xfffffe01 0xfffffe01 0xfffffe01 0xfffffe01 0xfffffe01 0xfffffe01 0xfffffe01 0xfffffe01 0xfffffe01 0xfffffe01 0xfffffe01 0xfffffe01 0xfffffe01 0xfffffe01 0xfffffe01 0xfffffe01 0xfffffe01 0xfffffe01 0xfffffe01 0xfffffe01 0xfffffe01 0xfffffe01 0xfffffe01 0xfffffe01 0xfffffe01 0xfffffe01 0xfffffe01 0xfffffe01 0xfffffe01 0xfffffe01 0xfffffe01 0xfffffe01 0xfffffe01 0xfffffe01 0xfffffe01 0xfffffe01 0xfffffe01 0xfffffe01 0xfffffe01 0xfffffe01 0xfffffe01 0xfffffe01 0xfffffe01 0xfffffe01 0xfffffe01 0xfffffe01 0xfffffe01 0xfffffe01 0xfffffe01 0xfffffe01 0xfffffe01 0xfffffe01 0xfffffe01 0xfffffe01 0xfffffe01 0xfffffe01 0xfffffe01 0xfffffe01 0xfffffe01 0xfffffe01 0xfffffe01 0xfffffe01 0xfffffe01 0xfffffe01 0xfffffe01 0xfffffe01 0xfffffe01 0xfffffe01 0xfffffe01 0xfffffe01 0xfffffe01 0xfffffe01 0xfffffe01 0xfffffe01 0xfffffe01 0xfffffe01 0xfffffe01 0xfffffe01 0xfffffe01 0xfffffe01 0xfffffe01 0xfffffe01 0xfffffe01 0xfffffe01 0xfffffe01 0xfffffe01 0xfffffe01 0xfffffe01 0xfffffe01 0xfffffe01 0xfffffe01 0xfffffe01 0xfffffe01 0xfffffe01 0xfffffe01 0xfffffe01 0xfffffe01 0xfffffe01 0xfffffe01 0xfffffe01 0xfffffe01 0xfffffe01 0xfffffe01 0xfffffe01 0xfffffe01 0xfffffe01 0xfffffe01 0xfffffe01 0xfffffe01 0xfffffe01 0xfffffe01 0xfffffe01 0xfffffe01 0xfffffe01 0xfffffe01 0xfffffe01 0xfffffe01 0xfffffe01 0xfffffe01 0xfffffe01 0xfffffe01 0xfffffe01 0xfffffe01 0xfffffe01 0xfffffe01 0xfffffe01 0xfffffe01 0xfffffe01 0xfffffe01 0xfffffe01 0xfffffe01 0xfffffe01 0xfffffe01 0xfffffe01 0xfffffe01 0xfffffe01 0xfffffe01 0xfffffe01 0xfffffe01 0xfffffe01 0xfffffe01 0xfffffe01 0xfffffe01 0xfffffe01 0xfffffe01 0xfffffe01 0xfffffe01 0xfffffe01 0xfffffe01 0xfffffe01 0xfffffe01 0xfffffe01 0xfffffe01 0xfffffe01 0xfffffe01 0xfffffe01 0xfffffe01 0xfffffe01 0xfffffe01 0xfffffe01 0xfffffe01 0xfffffe01 0xfffffe01 0xfffffe01 0xfffffe01 0xfffffe01 0xfffffe01 0xfffffe01 0xfffffe01 0xfffffe01 0xfffffe01 0xfffffe01 0xfffffe01 0xfffffe01 0xfffffe01 0xfffffe01 0xfffffe01 0xfffffe01 0xfffffe01 0xfffffe01 0xfffffe01 0xfffffe01 0xfffffe01 0xfffffe01 0xfffffe01 0xfffffe01 0xfffffe01 0xfffffe01 0xfffffe01 0xfffffe01 0xfffffe01 0xfffffe01 0xfffffe01 0xfffffe01 0xfffffe01 0xfffffe01 0xfffffe01 0xfffffe01 0xfffffe01 0xfffffe01 0xfffffe01 0xfffffe01 0xfffffe01 0xfffffe01 0xfffffe01 0xfffffe01 0xfffffe01 0xfffffe01 0xfffffe01 0xfffffe01 0xfffffe01 0xfffffe01 0xfffffe01 0xfffffe01 0xfffffe01 0xfffffe01 0xfffffe01 0xfffffe01 0xfffffe01 0xfffffe01 0xfffffe01 0xfffffe01 0xfffffe01 0xfffffe01 0xfffffe01 0xfffffe01 0xfffffe01 0xfffffe01 0xfffffe01 0xfffffe01 0xfffffe01 0xfffffe01 0xfffffe01 0xfffffe01 0xfffffe01 0xfffffe01 0xfffffe01 0xfffffe01 0xfffffe01 0xfffffe01 0xfffffe01 0xfffffe01 0xfffffe01 0xfffffe01 0xfffffe01 0xfffffe01 0xfffffe01 0xfffffe01 0xfffffe01 0xfffffe01 0xfffffe01 0xfffffe01 0xfffffe01 0xfffffe01 0xfffffe01 0xfffffe01 0xfffffe01 0xfffffe01 0xfffffe01 0xfffffe01 0xfffffe01 0xfffffe01 0xfffffe01 0xfffffe01 0xfffffe01 0xfffffe01 0xfffffe01 0xfffffe01 0xfffffe01 0xfffffe01 0xfffffe01 0xfffffe01 0xfffffe01 0xfffffe01 0xfffffe01 0xfffffe01 0xfffffe01 0xfffffe01 0xfffffe01 0xfffffe01 0xfffffe01 0xfffffe01 0xfffffe01 0xfffffe01 0xfffffe01 0xfffffe01 0xfffffe01 0xfffffe01 0xfffffe01 0xfffffe01 0xfffffe01 0xfffffe01 0xfffffe01 0xfffffe01 0xfffffe01 0xfffffe01 0xfffffe01 0xfffffe01 0xfffffe01 0xfffffe01 0xfffffe01 0xfffffe01 0xfffffe01 0xfffffe01 0xfffffe01 0xfffffe01 0xfffffe01 0xfffffe01 0xfffffe01 0xfffffe01 0xfffffe01 0xfffffe01 0xfffffe01 0xfffffe01 0xfffffe01 0xfffffe01 0xfffffe01 0xfffffe01 0xfffffe01 0xfffffe01 0xfffffe01 0xfffffe01 0xfffffe01 0xfffffe01 0xfffffe01 0xfffffe01 0xfffffe01 0xfffffe01 0xfffffe01 0xfffffe01 0xfffffe01 0xfffffe01 0xfffffe01 0xfffffe01 0xfffffe01 0xfffffe01 0xfffffe01 0xfffffe01 0xfffffe01 0xfffffe01 0xfffffe01 0xfffffe01 0xfffffe01 0xfffffe01 0xfffffe01 0xfffffe01 0xfffffe01 0xfffffe01 0xfffffe01 0xfffffe01 0xfffffe01 0xfffffe01 0xfffffe01 0xfffffe01 0xfffffe01 0xfffffe01 0xfffffe01 0xfffffe01 0xfffffe01 0xfffffe01 0xfffffe01 0xfffffe01 0xfffffe01 0xfffffe01 0xfffffe01 0xfffffe01 0xfffffe01 0xfffffe01 0xfffffe01 0xfffffe01 0xfffffe01 0xfffffe01 0xfffffe01 0xfffffe01 0xfffffe01 0xfffffe01 0xfffffe01 0xfffffe01 0xfffffe01 0xfffffe01 0xfffffe01 0xfffffe01 0xfffffe01 0xfffffe01 0xfffffe01 0xfffffe01 0xfffffe01 0xfffffe01 0xfffffe01 0xfffffe01 0xfffffe01 0xfffffe01 0xfffffe01 0xfffffe01 0xfffffe01 0xfffffe01 0xfffffe01 0xfffffe01 0xfffffe01 0xfffffe01 0xfffffe01 0xfffffe01 0xfffffe01 0xfffffe01 0xfffffe01 0xfffffe01 0xfffffe01 0xfffffe01 0xfffffe01 0xfffffe01 0xfffffe01 0xfffffe01 0xfffffe01 0xfffffe01 0xfffffe01 0xfffffe01 0xfffffe01 0xfffffe01 0xfffffe01 0xfffffe01 0xfffffe01 0xfffffe01 0xfffffe01 0xfffffe01 0xfffffe01 0xfffffe01 0xfffffe01 0xfffffe01 0xfffffe01 0xfffffe01 0xfffffe01 0xfffffe01 0xfffffe01 0xfffffe01 0xfffffe01 0xfffffe01 0xfffffe01 0xfffffe01 0xfffffe01 0xfffffe01 0xfffffe01 0xfffffe01 0xfffffe01 0xfffffe01 0xfffffe01 0xfffffe01 0xfffffe01 0xfffffe01 0xfffffe01 0xfffffe01 0xfffffe01 0xfffffe01 0xfffffe01 0xfffffe01 0xfffffe01 0xfffffe01 0xfffffe01 0xfffffe01 0xfffffe01 0xfffffe01 0xfffffe01 0xfffffe01 0xfffffe01 0xfffffe01 0xfffffe01 0xfffffe01 0xfffffe01 0xfffffe01 0xfffffe01 0xfffffe01 0xfffffe01 0xfffffe01 0xfffffe01 0xfffffe01 0xfffffe01 0xfffffe01 0xfffffe01 0xfffffe01 0xfffffe01 0xfffffe01 0xfffffe01 0xfffffe01 0xfffffe01 0xfffffe01 0xfffffe01 0xfffffe01 0xfffffe01 0xfffffe01 0xfffffe01 0xfffffe01 0xfffffe01 0xfffffe01 0xfffffe01 0xfffffe01 0xfffffe01 0xfffffe01 0xfffffe01>;
			PS_Config_Lmt_FW_Rawdata_P = <0xf00 0xf00 0xf00 0xf00 0xf00 0xf00 0xf00 0xf00 0xf00 0xf00 0xf00 0xf00 0xf00 0xf00 0xf00 0xf00 0xf00 0xf00 0xf00 0xf00 0xf00 0xf00 0xf00 0xf00 0xf00 0xf00 0xf00 0xf00 0xf00 0xf00 0xf00 0xf00 0xf00 0xf00 0xf00 0xf00 0xf00 0xf00 0xf00 0xf00 0xf00 0xf00 0xf00 0xf00 0xf00 0xf00 0xf00 0xf00 0xf00 0xf00 0xf00 0xf00 0xf00 0xf00 0xf00 0xf00 0xf00 0xf00 0xf00 0xf00 0xf00 0xf00 0xf00 0xf00 0xf00 0xf00 0xf00 0xf00 0xf00 0xf00 0xf00 0xf00 0xf00 0xf00 0xf00 0xf00 0xf00 0xf00 0xf00 0xf00 0xf00 0xf00 0xf00 0xf00 0xf00 0xf00 0xf00 0xf00 0xf00 0xf00 0xf00 0xf00 0xf00 0xf00 0xf00 0xf00 0xf00 0xf00 0xf00 0xf00 0xf00 0xf00 0xf00 0xf00 0xf00 0xf00 0xf00 0xf00 0xf00 0xf00 0xf00 0xf00 0xf00 0xf00 0xf00 0xf00 0xf00 0xf00 0xf00 0xf00 0xf00 0xf00 0xf00 0xf00 0xf00 0xf00 0xf00 0xf00 0xf00 0xf00 0xf00 0xf00 0xf00 0xf00 0xf00 0xf00 0xf00 0xf00 0xf00 0xf00 0xf00 0xf00 0xf00 0xf00 0xf00 0xf00 0xf00 0xf00 0xf00 0xf00 0xf00 0xf00 0xf00 0xf00 0xf00 0xf00 0xf00 0xf00 0xf00 0xf00 0xf00 0xf00 0xf00 0xf00 0xf00 0xf00 0xf00 0xf00 0xf00 0xf00 0xf00 0xf00 0xf00 0xf00 0xf00 0xf00 0xf00 0xf00 0xf00 0xf00 0xf00 0xf00 0xf00 0xf00 0xf00 0xf00 0xf00 0xf00 0xf00 0xf00 0xf00 0xf00 0xf00 0xf00 0xf00 0xf00 0xf00 0xf00 0xf00 0xf00 0xf00 0xf00 0xf00 0xf00 0xf00 0xf00 0xf00 0xf00 0xf00 0xf00 0xf00 0xf00 0xf00 0xf00 0xf00 0xf00 0xf00 0xf00 0xf00 0xf00 0xf00 0xf00 0xf00 0xf00 0xf00 0xf00 0xf00 0xf00 0xf00 0xf00 0xf00 0xf00 0xf00 0xf00 0xf00 0xf00 0xf00 0xf00 0xf00 0xf00 0xf00 0xf00 0xf00 0xf00 0xf00 0xf00 0xf00 0xf00 0xf00 0xf00 0xf00 0xf00 0xf00 0xf00 0xf00 0xf00 0xf00 0xf00 0xf00 0xf00 0xf00 0xf00 0xf00 0xf00 0xf00 0xf00 0xf00 0xf00 0xf00 0xf00 0xf00 0xf00 0xf00 0xf00 0xf00 0xf00 0xf00 0xf00 0xf00 0xf00 0xf00 0xf00 0xf00 0xf00 0xf00 0xf00 0xf00 0xf00 0xf00 0xf00 0xf00 0xf00 0xf00 0xf00 0xf00 0xf00 0xf00 0xf00 0xf00 0xf00 0xf00 0xf00 0xf00 0xf00 0xf00 0xf00 0xf00 0xf00 0xf00 0xf00 0xf00 0xf00 0xf00 0xf00 0xf00 0xf00 0xf00 0xf00 0xf00 0xf00 0xf00 0xf00 0xf00 0xf00 0xf00 0xf00 0xf00 0xf00 0xf00 0xf00 0xf00 0xf00 0xf00 0xf00 0xf00 0xf00 0xf00 0xf00 0xf00 0xf00 0xf00 0xf00 0xf00 0xf00 0xf00 0xf00 0xf00 0xf00 0xf00 0xf00 0xf00 0xf00 0xf00 0xf00 0xf00 0xf00 0xf00 0xf00 0xf00 0xf00 0xf00 0xf00 0xf00 0xf00 0xf00 0xf00 0xf00 0xf00 0xf00 0xf00 0xf00 0xf00 0xf00 0xf00 0xf00 0xf00 0xf00 0xf00 0xf00 0xf00 0xf00 0xf00 0xf00 0xf00 0xf00 0xf00 0xf00 0xf00 0xf00 0xf00 0xf00 0xf00 0xf00 0xf00 0xf00 0xf00 0xf00 0xf00 0xf00 0xf00 0xf00 0xf00 0xf00 0xf00 0xf00 0xf00 0xf00 0xf00 0xf00 0xf00 0xf00 0xf00 0xf00 0xf00 0xf00 0xf00 0xf00 0xf00 0xf00 0xf00 0xf00 0xf00 0xf00 0xf00 0xf00 0xf00 0xf00 0xf00 0xf00 0xf00 0xf00 0xf00 0xf00 0xf00 0xf00 0xf00 0xf00 0xf00 0xf00 0xf00 0xf00 0xf00 0xf00 0xf00 0xf00 0xf00 0xf00 0xf00 0xf00 0xf00 0xf00 0xf00 0xf00 0xf00 0xf00 0xf00 0xf00 0xf00 0xf00 0xf00 0xf00 0xf00 0xf00 0xf00 0xf00 0xf00 0xf00 0xf00 0xf00 0xf00 0xf00 0xf00 0xf00 0xf00 0xf00 0xf00 0xf00 0xf00 0xf00 0xf00 0xf00 0xf00 0xf00 0xf00 0xf00 0xf00 0xf00 0xf00 0xf00 0xf00 0xf00 0xf00 0xf00 0xf00 0xf00 0xf00 0xf00 0xf00 0xf00 0xf00 0xf00 0xf00 0xf00 0xf00 0xf00 0xf00 0xf00 0xf00 0xf00 0xf00 0xf00 0xf00 0xf00 0xf00 0xf00 0xf00 0xf00 0xf00 0xf00 0xf00 0xf00 0xf00 0xf00 0xf00 0xf00 0xf00 0xf00 0xf00 0xf00 0xf00 0xf00 0xf00 0xf00 0xf00 0xf00 0xf00 0xf00 0xf00 0xf00 0xf00 0xf00 0xf00 0xf00 0xf00 0xf00 0xf00 0xf00 0xf00 0xf00 0xf00 0xf00 0xf00 0xf00 0xf00 0xf00 0xf00 0xf00 0xf00 0xf00 0xf00 0xf00 0xf00 0xf00 0xf00 0xf00 0xf00 0xf00 0xf00 0xf00 0xf00 0xf00 0xf00 0xf00 0xf00 0xf00 0xf00 0xf00 0xf00 0xf00>;
			PS_Config_Lmt_FW_Rawdata_N = <0xf0 0xf0 0xf0 0xf0 0xf0 0xf0 0xf0 0xf0 0xf0 0xf0 0xf0 0xf0 0xf0 0xf0 0xf0 0xf0 0xf0 0xf0 0xf0 0xf0 0xf0 0xf0 0xf0 0xf0 0xf0 0xf0 0xf0 0xf0 0xf0 0xf0 0xf0 0xf0 0xf0 0xf0 0xf0 0xf0 0xf0 0xf0 0xf0 0xf0 0xf0 0xf0 0xf0 0xf0 0xf0 0xf0 0xf0 0xf0 0xf0 0xf0 0xf0 0xf0 0xf0 0xf0 0xf0 0xf0 0xf0 0xf0 0xf0 0xf0 0xf0 0xf0 0xf0 0xf0 0xf0 0xf0 0xf0 0xf0 0xf0 0xf0 0xf0 0xf0 0xf0 0xf0 0xf0 0xf0 0xf0 0xf0 0xf0 0xf0 0xf0 0xf0 0xf0 0xf0 0xf0 0xf0 0xf0 0xf0 0xf0 0xf0 0xf0 0xf0 0xf0 0xf0 0xf0 0xf0 0xf0 0xf0 0xf0 0xf0 0xf0 0xf0 0xf0 0xf0 0xf0 0xf0 0xf0 0xf0 0xf0 0xf0 0xf0 0xf0 0xf0 0xf0 0xf0 0xf0 0xf0 0xf0 0xf0 0xf0 0xf0 0xf0 0xf0 0xf0 0xf0 0xf0 0xf0 0xf0 0xf0 0xf0 0xf0 0xf0 0xf0 0xf0 0xf0 0xf0 0xf0 0xf0 0xf0 0xf0 0xf0 0xf0 0xf0 0xf0 0xf0 0xf0 0xf0 0xf0 0xf0 0xf0 0xf0 0xf0 0xf0 0xf0 0xf0 0xf0 0xf0 0xf0 0xf0 0xf0 0xf0 0xf0 0xf0 0xf0 0xf0 0xf0 0xf0 0xf0 0xf0 0xf0 0xf0 0xf0 0xf0 0xf0 0xf0 0xf0 0xf0 0xf0 0xf0 0xf0 0xf0 0xf0 0xf0 0xf0 0xf0 0xf0 0xf0 0xf0 0xf0 0xf0 0xf0 0xf0 0xf0 0xf0 0xf0 0xf0 0xf0 0xf0 0xf0 0xf0 0xf0 0xf0 0xf0 0xf0 0xf0 0xf0 0xf0 0xf0 0xf0 0xf0 0xf0 0xf0 0xf0 0xf0 0xf0 0xf0 0xf0 0xf0 0xf0 0xf0 0xf0 0xf0 0xf0 0xf0 0xf0 0xf0 0xf0 0xf0 0xf0 0xf0 0xf0 0xf0 0xf0 0xf0 0xf0 0xf0 0xf0 0xf0 0xf0 0xf0 0xf0 0xf0 0xf0 0xf0 0xf0 0xf0 0xf0 0xf0 0xf0 0xf0 0xf0 0xf0 0xf0 0xf0 0xf0 0xf0 0xf0 0xf0 0xf0 0xf0 0xf0 0xf0 0xf0 0xf0 0xf0 0xf0 0xf0 0xf0 0xf0 0xf0 0xf0 0xf0 0xf0 0xf0 0xf0 0xf0 0xf0 0xf0 0xf0 0xf0 0xf0 0xf0 0xf0 0xf0 0xf0 0xf0 0xf0 0xf0 0xf0 0xf0 0xf0 0xf0 0xf0 0xf0 0xf0 0xf0 0xf0 0xf0 0xf0 0xf0 0xf0 0xf0 0xf0 0xf0 0xf0 0xf0 0xf0 0xf0 0xf0 0xf0 0xf0 0xf0 0xf0 0xf0 0xf0 0xf0 0xf0 0xf0 0xf0 0xf0 0xf0 0xf0 0xf0 0xf0 0xf0 0xf0 0xf0 0xf0 0xf0 0xf0 0xf0 0xf0 0xf0 0xf0 0xf0 0xf0 0xf0 0xf0 0xf0 0xf0 0xf0 0xf0 0xf0 0xf0 0xf0 0xf0 0xf0 0xf0 0xf0 0xf0 0xf0 0xf0 0xf0 0xf0 0xf0 0xf0 0xf0 0xf0 0xf0 0xf0 0xf0 0xf0 0xf0 0xf0 0xf0 0xf0 0xf0 0xf0 0xf0 0xf0 0xf0 0xf0 0xf0 0xf0 0xf0 0xf0 0xf0 0xf0 0xf0 0xf0 0xf0 0xf0 0xf0 0xf0 0xf0 0xf0 0xf0 0xf0 0xf0 0xf0 0xf0 0xf0 0xf0 0xf0 0xf0 0xf0 0xf0 0xf0 0xf0 0xf0 0xf0 0xf0 0xf0 0xf0 0xf0 0xf0 0xf0 0xf0 0xf0 0xf0 0xf0 0xf0 0xf0 0xf0 0xf0 0xf0 0xf0 0xf0 0xf0 0xf0 0xf0 0xf0 0xf0 0xf0 0xf0 0xf0 0xf0 0xf0 0xf0 0xf0 0xf0 0xf0 0xf0 0xf0 0xf0 0xf0 0xf0 0xf0 0xf0 0xf0 0xf0 0xf0 0xf0 0xf0 0xf0 0xf0 0xf0 0xf0 0xf0 0xf0 0xf0 0xf0 0xf0 0xf0 0xf0 0xf0 0xf0 0xf0 0xf0 0xf0 0xf0 0xf0 0xf0 0xf0 0xf0 0xf0 0xf0 0xf0 0xf0 0xf0 0xf0 0xf0 0xf0 0xf0 0xf0 0xf0 0xf0 0xf0 0xf0 0xf0 0xf0 0xf0 0xf0 0xf0 0xf0 0xf0 0xf0 0xf0 0xf0 0xf0 0xf0 0xf0 0xf0 0xf0 0xf0 0xf0 0xf0 0xf0 0xf0 0xf0 0xf0 0xf0 0xf0 0xf0 0xf0 0xf0 0xf0 0xf0 0xf0 0xf0 0xf0 0xf0 0xf0 0xf0 0xf0 0xf0 0xf0 0xf0 0xf0 0xf0 0xf0 0xf0 0xf0 0xf0 0xf0 0xf0 0xf0 0xf0 0xf0 0xf0 0xf0 0xf0 0xf0 0xf0 0xf0 0xf0 0xf0 0xf0 0xf0 0xf0 0xf0 0xf0 0xf0 0xf0 0xf0 0xf0 0xf0 0xf0 0xf0 0xf0 0xf0 0xf0 0xf0 0xf0 0xf0 0xf0 0xf0 0xf0 0xf0 0xf0 0xf0 0xf0 0xf0 0xf0 0xf0 0xf0 0xf0 0xf0 0xf0 0xf0 0xf0 0xf0 0xf0 0xf0 0xf0 0xf0 0xf0 0xf0 0xf0>;
			PS_Config_Lmt_FW_CC_P = <0x13a 0x13a 0x13a 0x13a 0x13a 0x13a 0x13a 0x13a 0x13a 0x13a 0x13a 0x13a 0x13a 0x13a 0x13a 0x13a 0x13a 0x13a 0x13a 0x13a 0x13a 0x13a 0x13a 0x13a 0x13a 0x13a 0x13a 0x13a 0x13a 0x13a 0x13a 0x13a 0x13a 0x13a 0x13a 0x13a 0x13a 0x13a 0x13a 0x13a 0x13a 0x13a 0x13a 0x13a 0x13a 0x13a 0x13a 0x13a 0x13a 0x13a 0x13a 0x13a 0x13a 0x13a 0x13a 0x13a 0x13a 0x13a 0x13a 0x13a 0x13a 0x13a 0x13a 0x13a 0x13a 0x13a 0x13a 0x13a 0x13a 0x13a 0x13a 0x13a 0x13a 0x13a 0x13a 0x13a 0x13a 0x13a 0x13a 0x13a 0x13a 0x13a 0x13a 0x13a 0x13a 0x13a 0x13a 0x13a 0x13a 0x13a 0x13a 0x13a 0x13a 0x13a 0x13a 0x13a 0x13a 0x13a 0x13a 0x13a 0x13a 0x13a 0x13a 0x13a 0x13a 0x13a 0x13a 0x13a 0x13a 0x13a 0x13a 0x13a 0x13a 0x13a 0x13a 0x13a 0x13a 0x13a 0x13a 0x13a 0x13a 0x13a 0x13a 0x13a 0x13a 0x13a 0x13a 0x13a 0x13a 0x13a 0x13a 0x13a 0x13a 0x13a 0x13a 0x13a 0x13a 0x13a 0x13a 0x13a 0x13a 0x13a 0x13a 0x13a 0x13a 0x13a 0x13a 0x13a 0x13a 0x13a 0x13a 0x13a 0x13a 0x13a 0x13a 0x13a 0x13a 0x13a 0x13a 0x13a 0x13a 0x13a 0x13a 0x13a 0x13a 0x13a 0x13a 0x13a 0x13a 0x13a 0x13a 0x13a 0x13a 0x13a 0x13a 0x13a 0x13a 0x13a 0x13a 0x13a 0x13a 0x13a 0x13a 0x13a 0x13a 0x13a 0x13a 0x13a 0x13a 0x13a 0x13a 0x13a 0x13a 0x13a 0x13a 0x13a 0x13a 0x13a 0x13a 0x13a 0x13a 0x13a 0x13a 0x13a 0x13a 0x13a 0x13a 0x13a 0x13a 0x13a 0x13a 0x13a 0x13a 0x13a 0x13a 0x13a 0x13a 0x13a 0x13a 0x13a 0x13a 0x13a 0x13a 0x13a 0x13a 0x13a 0x13a 0x13a 0x13a 0x13a 0x13a 0x13a 0x13a 0x13a 0x13a 0x13a 0x13a 0x13a 0x13a 0x13a 0x13a 0x13a 0x13a 0x13a 0x13a 0x13a 0x13a 0x13a 0x13a 0x13a 0x13a 0x13a 0x13a 0x13a 0x13a 0x13a 0x13a 0x13a 0x13a 0x13a 0x13a 0x13a 0x13a 0x13a 0x13a 0x13a 0x13a 0x13a 0x13a 0x13a 0x13a 0x13a 0x13a 0x13a 0x13a 0x13a 0x13a 0x13a 0x13a 0x13a 0x13a 0x13a 0x13a 0x13a 0x13a 0x13a 0x13a 0x13a 0x13a 0x13a 0x13a 0x13a 0x13a 0x13a 0x13a 0x13a 0x13a 0x13a 0x13a 0x13a 0x13a 0x13a 0x13a 0x13a 0x13a 0x13a 0x13a 0x13a 0x13a 0x13a 0x13a 0x13a 0x13a 0x13a 0x13a 0x13a 0x13a 0x13a 0x13a 0x13a 0x13a 0x13a 0x13a 0x13a 0x13a 0x13a 0x13a 0x13a 0x13a 0x13a 0x13a 0x13a 0x13a 0x13a 0x13a 0x13a 0x13a 0x13a 0x13a 0x13a 0x13a 0x13a 0x13a 0x13a 0x13a 0x13a 0x13a 0x13a 0x13a 0x13a 0x13a 0x13a 0x13a 0x13a 0x13a 0x13a 0x13a 0x13a 0x13a 0x13a 0x13a 0x13a 0x13a 0x13a 0x13a 0x13a 0x13a 0x13a 0x13a 0x13a 0x13a 0x13a 0x13a 0x13a 0x13a 0x13a 0x13a 0x13a 0x13a 0x13a 0x13a 0x13a 0x13a 0x13a 0x13a 0x13a 0x13a 0x13a 0x13a 0x13a 0x13a 0x13a 0x13a 0x13a 0x13a 0x13a 0x13a 0x13a 0x13a 0x13a 0x13a 0x13a 0x13a 0x13a 0x13a 0x13a 0x13a 0x13a 0x13a 0x13a 0x13a 0x13a 0x13a 0x13a 0x13a 0x13a 0x13a 0x13a 0x13a 0x13a 0x13a 0x13a 0x13a 0x13a 0x13a 0x13a 0x13a 0x13a 0x13a 0x13a 0x13a 0x13a 0x13a 0x13a 0x13a 0x13a 0x13a 0x13a 0x13a 0x13a 0x13a 0x13a 0x13a 0x13a 0x13a 0x13a 0x13a 0x13a 0x13a 0x13a 0x13a 0x13a 0x13a 0x13a 0x13a 0x13a 0x13a 0x13a 0x13a 0x13a 0x13a 0x13a 0x13a 0x13a 0x13a 0x13a 0x13a 0x13a 0x13a 0x13a 0x13a 0x13a 0x13a 0x13a 0x13a 0x13a 0x13a 0x13a 0x13a 0x13a 0x13a 0x13a 0x13a 0x13a 0x13a 0x13a 0x13a 0x13a 0x13a 0x13a 0x13a 0x13a 0x13a 0x13a 0x13a 0x13a 0x13a 0x13a 0x13a 0x13a 0x13a 0x13a 0x13a 0x13a 0x13a 0x13a 0x13a 0x13a 0x13a 0x13a 0x13a 0x13a 0x13a 0x13a 0x13a 0x13a 0x13a 0x13a 0x13a 0x13a 0x13a 0x13a 0x13a 0x13a 0x13a 0x13a 0x13a 0x13a 0x13a 0x13a 0x13a 0x13a 0x13a 0x13a 0x13a 0x13a 0x13a 0x13a 0x13a 0x13a 0x13a 0x13a 0x13a 0x13a 0x13a 0x13a 0x13a 0x13a 0x13a 0x13a 0x13a 0x13a 0x13a 0x13a 0x13a 0x13a 0x13a 0x13a 0x13a 0x13a 0x13a 0x13a 0x13a 0x13a 0x13a 0x13a 0x13a 0x13a 0x13a 0x13a 0x13a 0x13a 0x13a 0x13a 0x13a 0x13a 0x13a 0x13a 0x13a>;
			PS_Config_Lmt_FW_CC_N = <0x00 0x00 0x00 0x00 0x00 0x00 0x00 0x00 0x00 0x00 0x00 0x00 0x00 0x00 0x00 0x00 0x00 0x00 0x00 0x00 0x00 0x00 0x00 0x00 0x00 0x00 0x00 0x00 0x00 0x00 0x00 0x00 0x00 0x00 0x00 0x00 0x00 0x00 0x00 0x00 0x00 0x00 0x00 0x00 0x00 0x00 0x00 0x00 0x00 0x00 0x00 0x00 0x00 0x00 0x00 0x00 0x00 0x00 0x00 0x00 0x00 0x00 0x00 0x00 0x00 0x00 0x00 0x00 0x00 0x00 0x00 0x00 0x00 0x00 0x00 0x00 0x00 0x00 0x00 0x00 0x00 0x00 0x00 0x00 0x00 0x00 0x00 0x00 0x00 0x00 0x00 0x00 0x00 0x00 0x00 0x00 0x00 0x00 0x00 0x00 0x00 0x00 0x00 0x00 0x00 0x00 0x00 0x00 0x00 0x00 0x00 0x00 0x00 0x00 0x00 0x00 0x00 0x00 0x00 0x00 0x00 0x00 0x00 0x00 0x00 0x00 0x00 0x00 0x00 0x00 0x00 0x00 0x00 0x00 0x00 0x00 0x00 0x00 0x00 0x00 0x00 0x00 0x00 0x00 0x00 0x00 0x00 0x00 0x00 0x00 0x00 0x00 0x00 0x00 0x00 0x00 0x00 0x00 0x00 0x00 0x00 0x00 0x00 0x00 0x00 0x00 0x00 0x00 0x00 0x00 0x00 0x00 0x00 0x00 0x00 0x00 0x00 0x00 0x00 0x00 0x00 0x00 0x00 0x00 0x00 0x00 0x00 0x00 0x00 0x00 0x00 0x00 0x00 0x00 0x00 0x00 0x00 0x00 0x00 0x00 0x00 0x00 0x00 0x00 0x00 0x00 0x00 0x00 0x00 0x00 0x00 0x00 0x00 0x00 0x00 0x00 0x00 0x00 0x00 0x00 0x00 0x00 0x00 0x00 0x00 0x00 0x00 0x00 0x00 0x00 0x00 0x00 0x00 0x00 0x00 0x00 0x00 0x00 0x00 0x00 0x00 0x00 0x00 0x00 0x00 0x00 0x00 0x00 0x00 0x00 0x00 0x00 0x00 0x00 0x00 0x00 0x00 0x00 0x00 0x00 0x00 0x00 0x00 0x00 0x00 0x00 0x00 0x00 0x00 0x00 0x00 0x00 0x00 0x00 0x00 0x00 0x00 0x00 0x00 0x00 0x00 0x00 0x00 0x00 0x00 0x00 0x00 0x00 0x00 0x00 0x00 0x00 0x00 0x00 0x00 0x00 0x00 0x00 0x00 0x00 0x00 0x00 0x00 0x00 0x00 0x00 0x00 0x00 0x00 0x00 0x00 0x00 0x00 0x00 0x00 0x00 0x00 0x00 0x00 0x00 0x00 0x00 0x00 0x00 0x00 0x00 0x00 0x00 0x00 0x00 0x00 0x00 0x00 0x00 0x00 0x00 0x00 0x00 0x00 0x00 0x00 0x00 0x00 0x00 0x00 0x00 0x00 0x00 0x00 0x00 0x00 0x00 0x00 0x00 0x00 0x00 0x00 0x00 0x00 0x00 0x00 0x00 0x00 0x00 0x00 0x00 0x00 0x00 0x00 0x00 0x00 0x00 0x00 0x00 0x00 0x00 0x00 0x00 0x00 0x00 0x00 0x00 0x00 0x00 0x00 0x00 0x00 0x00 0x00 0x00 0x00 0x00 0x00 0x00 0x00 0x00 0x00 0x00 0x00 0x00 0x00 0x00 0x00 0x00 0x00 0x00 0x00 0x00 0x00 0x00 0x00 0x00 0x00 0x00 0x00 0x00 0x00 0x00 0x00 0x00 0x00 0x00 0x00 0x00 0x00 0x00 0x00 0x00 0x00 0x00 0x00 0x00 0x00 0x00 0x00 0x00 0x00 0x00 0x00 0x00 0x00 0x00 0x00 0x00 0x00 0x00 0x00 0x00 0x00 0x00 0x00 0x00 0x00 0x00 0x00 0x00 0x00 0x00 0x00 0x00 0x00 0x00 0x00 0x00 0x00 0x00 0x00 0x00 0x00 0x00 0x00 0x00 0x00 0x00 0x00 0x00 0x00 0x00 0x00 0x00 0x00 0x00 0x00 0x00 0x00 0x00 0x00 0x00 0x00 0x00 0x00 0x00 0x00 0x00 0x00 0x00 0x00 0x00 0x00 0x00 0x00 0x00 0x00 0x00 0x00 0x00 0x00 0x00 0x00 0x00 0x00 0x00 0x00 0x00 0x00 0x00 0x00 0x00 0x00 0x00 0x00 0x00 0x00 0x00 0x00 0x00 0x00 0x00 0x00 0x00 0x00 0x00 0x00 0x00 0x00 0x00 0x00 0x00 0x00 0x00 0x00 0x00 0x00 0x00 0x00 0x00 0x00 0x00 0x00 0x00 0x00 0x00 0x00 0x00 0x00 0x00 0x00 0x00 0x00 0x00 0x00 0x00 0x00 0x00 0x00 0x00 0x00 0x00 0x00 0x00 0x00 0x00 0x00 0x00 0x00 0x00 0x00 0x00 0x00>;
			PS_Config_Lmt_FW_Diff_P = <0x4b 0x4b 0x4b 0x4b 0x4b 0x4b 0x4b 0x4b 0x4b 0x4b 0x4b 0x4b 0x4b 0x4b 0x4b 0x4b 0x4b 0x4b 0x4b 0x4b 0x4b 0x4b 0x4b 0x4b 0x4b 0x4b 0x4b 0x4b 0x4b 0x4b 0x4b 0x4b 0x4b 0x4b 0x4b 0x4b 0x4b 0x4b 0x4b 0x4b 0x4b 0x4b 0x4b 0x4b 0x4b 0x4b 0x4b 0x4b 0x4b 0x4b 0x4b 0x4b 0x4b 0x4b 0x4b 0x4b 0x4b 0x4b 0x4b 0x4b 0x4b 0x4b 0x4b 0x4b 0x4b 0x4b 0x4b 0x4b 0x4b 0x4b 0x4b 0x4b 0x4b 0x4b 0x4b 0x4b 0x4b 0x4b 0x4b 0x4b 0x4b 0x4b 0x4b 0x4b 0x4b 0x4b 0x4b 0x4b 0x4b 0x4b 0x4b 0x4b 0x4b 0x4b 0x4b 0x4b 0x4b 0x4b 0x4b 0x4b 0x4b 0x4b 0x4b 0x4b 0x4b 0x4b 0x4b 0x4b 0x4b 0x4b 0x4b 0x4b 0x4b 0x4b 0x4b 0x4b 0x4b 0x4b 0x4b 0x4b 0x4b 0x4b 0x4b 0x4b 0x4b 0x4b 0x4b 0x4b 0x4b 0x4b 0x4b 0x4b 0x4b 0x4b 0x4b 0x4b 0x4b 0x4b 0x4b 0x4b 0x4b 0x4b 0x4b 0x4b 0x4b 0x4b 0x4b 0x4b 0x4b 0x4b 0x4b 0x4b 0x4b 0x4b 0x4b 0x4b 0x4b 0x4b 0x4b 0x4b 0x4b 0x4b 0x4b 0x4b 0x4b 0x4b 0x4b 0x4b 0x4b 0x4b 0x4b 0x4b 0x4b 0x4b 0x4b 0x4b 0x4b 0x4b 0x4b 0x4b 0x4b 0x4b 0x4b 0x4b 0x4b 0x4b 0x4b 0x4b 0x4b 0x4b 0x4b 0x4b 0x4b 0x4b 0x4b 0x4b 0x4b 0x4b 0x4b 0x4b 0x4b 0x4b 0x4b 0x4b 0x4b 0x4b 0x4b 0x4b 0x4b 0x4b 0x4b 0x4b 0x4b 0x4b 0x4b 0x4b 0x4b 0x4b 0x4b 0x4b 0x4b 0x4b 0x4b 0x4b 0x4b 0x4b 0x4b 0x4b 0x4b 0x4b 0x4b 0x4b 0x4b 0x4b 0x4b 0x4b 0x4b 0x4b 0x4b 0x4b 0x4b 0x4b 0x4b 0x4b 0x4b 0x4b 0x4b 0x4b 0x4b 0x4b 0x4b 0x4b 0x4b 0x4b 0x4b 0x4b 0x4b 0x4b 0x4b 0x4b 0x4b 0x4b 0x4b 0x4b 0x4b 0x4b 0x4b 0x4b 0x4b 0x4b 0x4b 0x4b 0x4b 0x4b 0x4b 0x4b 0x4b 0x4b 0x4b 0x4b 0x4b 0x4b 0x4b 0x4b 0x4b 0x4b 0x4b 0x4b 0x4b 0x4b 0x4b 0x4b 0x4b 0x4b 0x4b 0x4b 0x4b 0x4b 0x4b 0x4b 0x4b 0x4b 0x4b 0x4b 0x4b 0x4b 0x4b 0x4b 0x4b 0x4b 0x4b 0x4b 0x4b 0x4b 0x4b 0x4b 0x4b 0x4b 0x4b 0x4b 0x4b 0x4b 0x4b 0x4b 0x4b 0x4b 0x4b 0x4b 0x4b 0x4b 0x4b 0x4b 0x4b 0x4b 0x4b 0x4b 0x4b 0x4b 0x4b 0x4b 0x4b 0x4b 0x4b 0x4b 0x4b 0x4b 0x4b 0x4b 0x4b 0x4b 0x4b 0x4b 0x4b 0x4b 0x4b 0x4b 0x4b 0x4b 0x4b 0x4b 0x4b 0x4b 0x4b 0x4b 0x4b 0x4b 0x4b 0x4b 0x4b 0x4b 0x4b 0x4b 0x4b 0x4b 0x4b 0x4b 0x4b 0x4b 0x4b 0x4b 0x4b 0x4b 0x4b 0x4b 0x4b 0x4b 0x4b 0x4b 0x4b 0x4b 0x4b 0x4b 0x4b 0x4b 0x4b 0x4b 0x4b 0x4b 0x4b 0x4b 0x4b 0x4b 0x4b 0x4b 0x4b 0x4b 0x4b 0x4b 0x4b 0x4b 0x4b 0x4b 0x4b 0x4b 0x4b 0x4b 0x4b 0x4b 0x4b 0x4b 0x4b 0x4b 0x4b 0x4b 0x4b 0x4b 0x4b 0x4b 0x4b 0x4b 0x4b 0x4b 0x4b 0x4b 0x4b 0x4b 0x4b 0x4b 0x4b 0x4b 0x4b 0x4b 0x4b 0x4b 0x4b 0x4b 0x4b 0x4b 0x4b 0x4b 0x4b 0x4b 0x4b 0x4b 0x4b 0x4b 0x4b 0x4b 0x4b 0x4b 0x4b 0x4b 0x4b 0x4b 0x4b 0x4b 0x4b 0x4b 0x4b 0x4b 0x4b 0x4b 0x4b 0x4b 0x4b 0x4b 0x4b 0x4b 0x4b 0x4b 0x4b 0x4b 0x4b 0x4b 0x4b 0x4b 0x4b 0x4b 0x4b 0x4b 0x4b 0x4b 0x4b 0x4b 0x4b 0x4b 0x4b 0x4b 0x4b 0x4b 0x4b 0x4b 0x4b 0x4b 0x4b 0x4b 0x4b 0x4b 0x4b 0x4b 0x4b 0x4b 0x4b 0x4b 0x4b 0x4b 0x4b 0x4b 0x4b 0x4b 0x4b 0x4b 0x4b 0x4b 0x4b 0x4b 0x4b 0x4b 0x4b 0x4b 0x4b 0x4b 0x4b 0x4b 0x4b 0x4b 0x4b 0x4b 0x4b 0x4b 0x4b 0x4b 0x4b 0x4b 0x4b 0x4b 0x4b 0x4b 0x4b 0x4b 0x4b 0x4b 0x4b 0x4b 0x4b 0x4b 0x4b 0x4b 0x4b 0x4b 0x4b 0x4b 0x4b 0x4b 0x4b 0x4b 0x4b 0x4b 0x4b 0x4b 0x4b 0x4b 0x4b 0x4b 0x4b 0x4b 0x4b 0x4b 0x4b>;
			PS_Config_Lmt_FW_Diff_N = <0xffffffb5 0xffffffb5 0xffffffb5 0xffffffb5 0xffffffb5 0xffffffb5 0xffffffb5 0xffffffb5 0xffffffb5 0xffffffb5 0xffffffb5 0xffffffb5 0xffffffb5 0xffffffb5 0xffffffb5 0xffffffb5 0xffffffb5 0xffffffb5 0xffffffb5 0xffffffb5 0xffffffb5 0xffffffb5 0xffffffb5 0xffffffb5 0xffffffb5 0xffffffb5 0xffffffb5 0xffffffb5 0xffffffb5 0xffffffb5 0xffffffb5 0xffffffb5 0xffffffb5 0xffffffb5 0xffffffb5 0xffffffb5 0xffffffb5 0xffffffb5 0xffffffb5 0xffffffb5 0xffffffb5 0xffffffb5 0xffffffb5 0xffffffb5 0xffffffb5 0xffffffb5 0xffffffb5 0xffffffb5 0xffffffb5 0xffffffb5 0xffffffb5 0xffffffb5 0xffffffb5 0xffffffb5 0xffffffb5 0xffffffb5 0xffffffb5 0xffffffb5 0xffffffb5 0xffffffb5 0xffffffb5 0xffffffb5 0xffffffb5 0xffffffb5 0xffffffb5 0xffffffb5 0xffffffb5 0xffffffb5 0xffffffb5 0xffffffb5 0xffffffb5 0xffffffb5 0xffffffb5 0xffffffb5 0xffffffb5 0xffffffb5 0xffffffb5 0xffffffb5 0xffffffb5 0xffffffb5 0xffffffb5 0xffffffb5 0xffffffb5 0xffffffb5 0xffffffb5 0xffffffb5 0xffffffb5 0xffffffb5 0xffffffb5 0xffffffb5 0xffffffb5 0xffffffb5 0xffffffb5 0xffffffb5 0xffffffb5 0xffffffb5 0xffffffb5 0xffffffb5 0xffffffb5 0xffffffb5 0xffffffb5 0xffffffb5 0xffffffb5 0xffffffb5 0xffffffb5 0xffffffb5 0xffffffb5 0xffffffb5 0xffffffb5 0xffffffb5 0xffffffb5 0xffffffb5 0xffffffb5 0xffffffb5 0xffffffb5 0xffffffb5 0xffffffb5 0xffffffb5 0xffffffb5 0xffffffb5 0xffffffb5 0xffffffb5 0xffffffb5 0xffffffb5 0xffffffb5 0xffffffb5 0xffffffb5 0xffffffb5 0xffffffb5 0xffffffb5 0xffffffb5 0xffffffb5 0xffffffb5 0xffffffb5 0xffffffb5 0xffffffb5 0xffffffb5 0xffffffb5 0xffffffb5 0xffffffb5 0xffffffb5 0xffffffb5 0xffffffb5 0xffffffb5 0xffffffb5 0xffffffb5 0xffffffb5 0xffffffb5 0xffffffb5 0xffffffb5 0xffffffb5 0xffffffb5 0xffffffb5 0xffffffb5 0xffffffb5 0xffffffb5 0xffffffb5 0xffffffb5 0xffffffb5 0xffffffb5 0xffffffb5 0xffffffb5 0xffffffb5 0xffffffb5 0xffffffb5 0xffffffb5 0xffffffb5 0xffffffb5 0xffffffb5 0xffffffb5 0xffffffb5 0xffffffb5 0xffffffb5 0xffffffb5 0xffffffb5 0xffffffb5 0xffffffb5 0xffffffb5 0xffffffb5 0xffffffb5 0xffffffb5 0xffffffb5 0xffffffb5 0xffffffb5 0xffffffb5 0xffffffb5 0xffffffb5 0xffffffb5 0xffffffb5 0xffffffb5 0xffffffb5 0xffffffb5 0xffffffb5 0xffffffb5 0xffffffb5 0xffffffb5 0xffffffb5 0xffffffb5 0xffffffb5 0xffffffb5 0xffffffb5 0xffffffb5 0xffffffb5 0xffffffb5 0xffffffb5 0xffffffb5 0xffffffb5 0xffffffb5 0xffffffb5 0xffffffb5 0xffffffb5 0xffffffb5 0xffffffb5 0xffffffb5 0xffffffb5 0xffffffb5 0xffffffb5 0xffffffb5 0xffffffb5 0xffffffb5 0xffffffb5 0xffffffb5 0xffffffb5 0xffffffb5 0xffffffb5 0xffffffb5 0xffffffb5 0xffffffb5 0xffffffb5 0xffffffb5 0xffffffb5 0xffffffb5 0xffffffb5 0xffffffb5 0xffffffb5 0xffffffb5 0xffffffb5 0xffffffb5 0xffffffb5 0xffffffb5 0xffffffb5 0xffffffb5 0xffffffb5 0xffffffb5 0xffffffb5 0xffffffb5 0xffffffb5 0xffffffb5 0xffffffb5 0xffffffb5 0xffffffb5 0xffffffb5 0xffffffb5 0xffffffb5 0xffffffb5 0xffffffb5 0xffffffb5 0xffffffb5 0xffffffb5 0xffffffb5 0xffffffb5 0xffffffb5 0xffffffb5 0xffffffb5 0xffffffb5 0xffffffb5 0xffffffb5 0xffffffb5 0xffffffb5 0xffffffb5 0xffffffb5 0xffffffb5 0xffffffb5 0xffffffb5 0xffffffb5 0xffffffb5 0xffffffb5 0xffffffb5 0xffffffb5 0xffffffb5 0xffffffb5 0xffffffb5 0xffffffb5 0xffffffb5 0xffffffb5 0xffffffb5 0xffffffb5 0xffffffb5 0xffffffb5 0xffffffb5 0xffffffb5 0xffffffb5 0xffffffb5 0xffffffb5 0xffffffb5 0xffffffb5 0xffffffb5 0xffffffb5 0xffffffb5 0xffffffb5 0xffffffb5 0xffffffb5 0xffffffb5 0xffffffb5 0xffffffb5 0xffffffb5 0xffffffb5 0xffffffb5 0xffffffb5 0xffffffb5 0xffffffb5 0xffffffb5 0xffffffb5 0xffffffb5 0xffffffb5 0xffffffb5 0xffffffb5 0xffffffb5 0xffffffb5 0xffffffb5 0xffffffb5 0xffffffb5 0xffffffb5 0xffffffb5 0xffffffb5 0xffffffb5 0xffffffb5 0xffffffb5 0xffffffb5 0xffffffb5 0xffffffb5 0xffffffb5 0xffffffb5 0xffffffb5 0xffffffb5 0xffffffb5 0xffffffb5 0xffffffb5 0xffffffb5 0xffffffb5 0xffffffb5 0xffffffb5 0xffffffb5 0xffffffb5 0xffffffb5 0xffffffb5 0xffffffb5 0xffffffb5 0xffffffb5 0xffffffb5 0xffffffb5 0xffffffb5 0xffffffb5 0xffffffb5 0xffffffb5 0xffffffb5 0xffffffb5 0xffffffb5 0xffffffb5 0xffffffb5 0xffffffb5 0xffffffb5 0xffffffb5 0xffffffb5 0xffffffb5 0xffffffb5 0xffffffb5 0xffffffb5 0xffffffb5 0xffffffb5 0xffffffb5 0xffffffb5 0xffffffb5 0xffffffb5 0xffffffb5 0xffffffb5 0xffffffb5 0xffffffb5 0xffffffb5 0xffffffb5 0xffffffb5 0xffffffb5 0xffffffb5 0xffffffb5 0xffffffb5 0xffffffb5 0xffffffb5 0xffffffb5 0xffffffb5 0xffffffb5 0xffffffb5 0xffffffb5 0xffffffb5 0xffffffb5 0xffffffb5 0xffffffb5 0xffffffb5 0xffffffb5 0xffffffb5 0xffffffb5 0xffffffb5 0xffffffb5 0xffffffb5 0xffffffb5 0xffffffb5 0xffffffb5 0xffffffb5 0xffffffb5 0xffffffb5 0xffffffb5 0xffffffb5 0xffffffb5 0xffffffb5 0xffffffb5 0xffffffb5 0xffffffb5 0xffffffb5 0xffffffb5 0xffffffb5 0xffffffb5 0xffffffb5 0xffffffb5 0xffffffb5 0xffffffb5 0xffffffb5 0xffffffb5 0xffffffb5 0xffffffb5 0xffffffb5 0xffffffb5 0xffffffb5 0xffffffb5 0xffffffb5 0xffffffb5 0xffffffb5 0xffffffb5 0xffffffb5 0xffffffb5 0xffffffb5 0xffffffb5 0xffffffb5 0xffffffb5 0xffffffb5 0xffffffb5 0xffffffb5 0xffffffb5 0xffffffb5 0xffffffb5 0xffffffb5 0xffffffb5 0xffffffb5 0xffffffb5 0xffffffb5 0xffffffb5 0xffffffb5 0xffffffb5 0xffffffb5 0xffffffb5 0xffffffb5 0xffffffb5 0xffffffb5 0xffffffb5 0xffffffb5 0xffffffb5 0xffffffb5 0xffffffb5 0xffffffb5 0xffffffb5 0xffffffb5 0xffffffb5 0xffffffb5 0xffffffb5 0xffffffb5 0xffffffb5 0xffffffb5 0xffffffb5 0xffffffb5 0xffffffb5 0xffffffb5 0xffffffb5 0xffffffb5 0xffffffb5 0xffffffb5 0xffffffb5 0xffffffb5 0xffffffb5 0xffffffb5 0xffffffb5 0xffffffb5 0xffffffb5 0xffffffb5 0xffffffb5 0xffffffb5 0xffffffb5 0xffffffb5 0xffffffb5 0xffffffb5 0xffffffb5 0xffffffb5 0xffffffb5 0xffffffb5 0xffffffb5 0xffffffb5 0xffffffb5 0xffffffb5 0xffffffb5 0xffffffb5 0xffffffb5 0xffffffb5 0xffffffb5 0xffffffb5 0xffffffb5 0xffffffb5 0xffffffb5 0xffffffb5 0xffffffb5 0xffffffb5 0xffffffb5 0xffffffb5 0xffffffb5 0xffffffb5 0xffffffb5 0xffffffb5 0xffffffb5 0xffffffb5 0xffffffb5 0xffffffb5 0xffffffb5 0xffffffb5 0xffffffb5 0xffffffb5 0xffffffb5 0xffffffb5 0xffffffb5 0xffffffb5 0xffffffb5 0xffffffb5 0xffffffb5 0xffffffb5 0xffffffb5 0xffffffb5 0xffffffb5 0xffffffb5 0xffffffb5 0xffffffb5 0xffffffb5 0xffffffb5 0xffffffb5 0xffffffb5 0xffffffb5 0xffffffb5 0xffffffb5 0xffffffb5 0xffffffb5 0xffffffb5 0xffffffb5 0xffffffb5 0xffffffb5 0xffffffb5 0xffffffb5 0xffffffb5 0xffffffb5 0xffffffb5 0xffffffb5 0xffffffb5 0xffffffb5 0xffffffb5 0xffffffb5 0xffffffb5 0xffffffb5 0xffffffb5 0xffffffb5 0xffffffb5 0xffffffb5 0xffffffb5 0xffffffb5 0xffffffb5 0xffffffb5 0xffffffb5>;
			PS_Config_Diff_Test_Frame = <0x32>;
		};
	};
};

&pm8150_gpios {
	vol_up_pin_a: vol-up-active {
		pins = "gpio6";
		function = "normal";
		input-enable;
		bias-pull-up;
		qcom,drive-strength = <PMIC_GPIO_STRENGTH_NO>;
	};
};


&gpi_dma0 {
	status = "okay";
};

&gpi_dma1 {
	status = "okay";
};

&gpi_dma2 {
	status = "okay";
};

&pon_pwrkey {
	status = "okay";
};

&pon_resin {
	status = "okay";

	linux,code = <KEY_VOLUMEDOWN>;
};

&qupv3_id_0 {
	status = "okay";
};

&qupv3_id_1 {
	status = "okay";
};

&qupv3_id_2 {
	status = "okay";
};

&remoteproc_adsp {
	status = "okay";
	firmware-name = "qcom/sm8150/vayu/adsp.mbn";
};

&remoteproc_cdsp {
	status = "okay";
	firmware-name = "qcom/sm8150/vayu/cdsp.mbn";
};

&remoteproc_mpss {
	status = "okay";
	firmware-name = "qcom/sm8150/vayu/modem.mbn";
};

&tlmm {
	/* gpios 0..3 are NFC spi, gpios 126..129 are FP spi */
	gpio-reserved-ranges = <0 4>, <126 4>;
	
	ts_int_active: ts_int_active {
		pins = "gpio122";
		function = "gpio";
		drive-strength = <16>;
		bias-pull-down;
	};

	ts_reset_active: ts_reset_active {
		pins = "gpio12";
		function = "gpio";
		drive-strength = <16>;
		bias-pull-up;
	};

	ts_cs_active: ts_cs_active {
		pins = "gpio58";
		function = "qup17";
		drive-strength = <6>;
		bias-disable;
	};

	ts_cs_suspend: ts_cs_suspend {
		pins = "gpio58";
		function = "gpio";
		drive-strength = <6>;
		bias-pull-down;
		output-low;
	};
			
	ts_int_suspend: ts_int_suspend {
		pins = "gpio122";
		function = "gpio";
		drive-strength = <16>;
		bias-disable;
		input-enable;
	};

	ts_reset_suspend: ts_reset_suspend {
		pins = "gpio12";
		function = "gpio";
		drive-strength = <16>;
		bias-disable;
	};

	sdc2_on: sdc2-on-state {
		clk-pins {
			pins = "sdc2_clk";
			bias-disable;
			drive-strength = <16>;
		};

		cmd-pins {
			pins = "sdc2_cmd";
			bias-pull-up;
			drive-strength = <16>;
		};

		data-pins {
			pins = "sdc2_data";
			bias-pull-up;
			drive-strength = <16>;
		};

		sd-cd-pins {
			pins = "gpio96";
			function = "gpio";
			bias-pull-up;
			drive-strength = <2>;
		};
	};

	sdc2_off: sdc2-off-state {
		clk-pins {
			pins = "sdc2_clk";
			bias-disable;
			drive-strength = <2>;
		};

		cmd-pins {
			pins = "sdc2_cmd";
			bias-pull-up;
			drive-strength = <2>;
		};

		data-pins {
			pins = "sdc2_data";
			bias-pull-up;
			drive-strength = <2>;
		};

		sd-cd-pins {
			pins = "gpio96";
			function = "gpio";
			bias-pull-up;
			drive-strength = <2>;
		};
	};

	qup_uart13_sleep: qup-uart13-sleep {
		pinmux {
			pins = "gpio43", "gpio44", "gpio45", "gpio46";
			function = "gpio";
		};

		pinconf-cts {
			/*
			 * Configure a pull-down on CTS to match the pull of
			 * the Bluetooth module.
			 */
			pins = "gpio43";
			bias-pull-down;
		};

		pinconf-rts {
			/*
			 * Configure pull-down on RTS. As RTS is active low
			 * signal, pull it low to indicate the BT SoC that it
			 * can wakeup the system anytime from suspend state by
			 * pulling RX low (by sending wakeup bytes).
			 */
			 pins = "gpio44";
			 bias-pull-down;
		};

		pinconf-tx {
			/*
			 * Configure pull-up on TX when it isn't actively driven
			 * to prevent BT SoC from receiving garbage during sleep.
			 */
			pins = "gpio45";
			bias-pull-up;
		};

		pinconf-rx {
			/*
			 * Configure a pull-up on RX. This is needed to avoid
			 * garbage data when the TX pin of the Bluetooth module
			 * is floating which may cause spurious wakeups.
			 */
			pins = "gpio46";
			bias-pull-up;
		};
	};

	bl_en_state: bl-default-state {
		bl-en {
			pins = "gpio27";
			function = "gpio";

			drive-strength = <16>;
			output-high;
			bias-disable;
		};
	};
};

&uart2 {
	status = "okay";
};

&uart13 {
	status = "okay";

	/delete-property/interrupts;
	interrupts-extended = <&intc GIC_SPI 585 IRQ_TYPE_LEVEL_HIGH>,
	                      <&tlmm 46 IRQ_TYPE_EDGE_FALLING>;

	pinctrl-names = "default", "sleep";
	pinctrl-1 = <&qup_uart13_sleep>;

	bluetooth: bluetooth {
		compatible = "qcom,wcn3990-bt";
		vddio-supply = <&vreg_l1a_0p75>;
		vddxo-supply = <&vreg_l7a_1p8>;
		vddrf-supply = <&vreg_l2c_1p3>;
		vddch0-supply = <&vreg_l11c_3p3>;
		max-speed = <3200000>;
		firmware-name = "vayu/crnv21.bin";
	};
};

&ufs_mem_hc {
	status = "okay";

	reset-gpios = <&tlmm 175 GPIO_ACTIVE_LOW>;

	vcc-supply = <&vreg_l10a_2p5>;
	vcc-max-microamp = <750000>;
	vccq-supply = <&vreg_l9a_1p2>;
	vccq-max-microamp = <700000>;
	vccq2-supply = <&vreg_s4a_1p8>;
	vccq2-max-microamp = <750000>;
};

&ufs_mem_phy {
	status = "okay";

	vdda-phy-supply = <&vdda_ufs_2ln_core_1>;
	vdda-max-microamp = <90200>;
	vdda-pll-supply = <&vreg_l3c_1p2>;
	vdda-pll-max-microamp = <19000>;
};

&usb_1 {
	status = "okay";
};

&usb_1_dwc3 {
	snps,has-lpm-erratum;
	snps,hird-threshold = /bits/ 8 <0x10>;
	maximum-speed = "high-speed";
	dr_mode = "peripheral";
};

&usb_1_hsphy {
	status = "okay";
	vdda-pll-supply = <&vreg_l5a_0p875>;
	vdda18-supply = <&vreg_l12a_1p8>;
	vdda33-supply = <&vreg_l2a_3p1>;
};

&usb_1_qmpphy {
	status = "okay";
	vdda-phy-supply = <&vreg_l3c_1p2>;
	vdda-pll-supply = <&vreg_l5a_0p875>;
};

&wifi {
	status = "okay";

	vdd-0.8-cx-mx-supply = <&vdda_wcss_pll>;
	vdd-1.8-xo-supply = <&vreg_l7a_1p8>;
	vdd-1.3-rfa-supply = <&vdda_wcss_adcdac_1>;
	vdd-3.3-ch0-supply = <&vreg_l11c_3p3>;
};

&sdhc_2 {
	status = "okay";

	pinctrl-names = "default", "sleep";
	pinctrl-0 = <&sdc2_on>;
	pinctrl-1 = <&sdc2_off>;
	vmmc-supply = <&vreg_l9c_2p9>;
	vqmmc-supply = <&vreg_l6c_2p9>;

	cd-gpios = <&tlmm 96 GPIO_ACTIVE_HIGH>;
};
